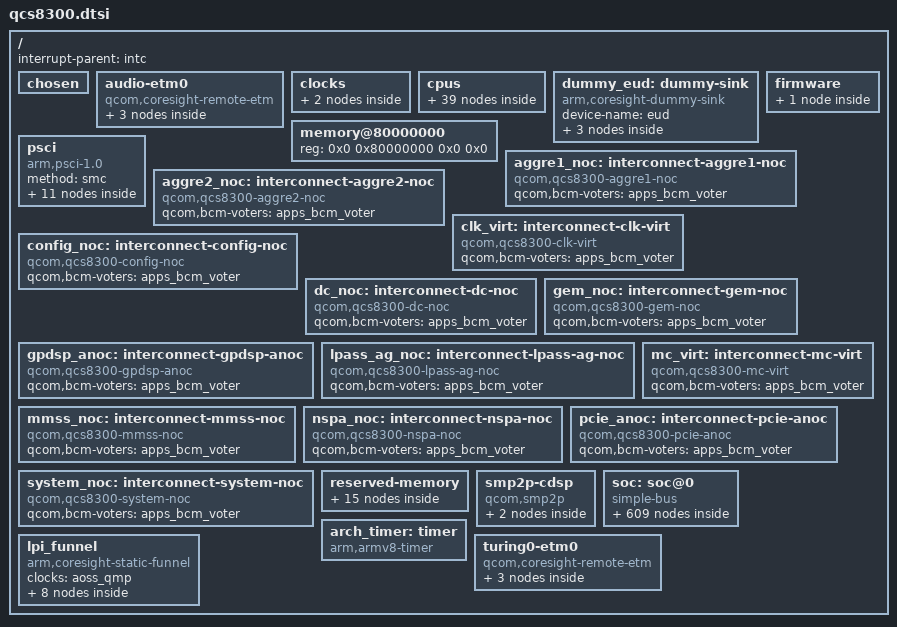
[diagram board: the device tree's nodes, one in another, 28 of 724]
// SPDX-License-Identifier: BSD-3-Clause
/*
 * Copyright (c) 2024 Qualcomm Innovation Center, Inc. All rights reserved.
 */

#include <dt-bindings/clock/qcom,qcs8300-gcc.h>
#include <dt-bindings/clock/qcom,rpmh.h>
#include <dt-bindings/clock/qcom,sa8775p-camcc.h>
#include <dt-bindings/clock/qcom,sa8775p-dispcc.h>
#include <dt-bindings/clock/qcom,sa8775p-gpucc.h>
#include <dt-bindings/clock/qcom,sa8775p-videocc.h>
#include <dt-bindings/interconnect/qcom,icc.h>
#include <dt-bindings/interconnect/qcom,qcs8300-rpmh.h>
#include <dt-bindings/interrupt-controller/arm-gic.h>
#include <dt-bindings/mailbox/qcom-ipcc.h>
#include <dt-bindings/power/qcom,rpmhpd.h>
#include <dt-bindings/power/qcom-rpmpd.h>
#include <dt-bindings/soc/qcom,rpmh-rsc.h>

/ {
	interrupt-parent = <&intc>;

	#address-cells = <2>;
	#size-cells = <2>;

	chosen { };

	audio-etm0 {
		compatible = "qcom,coresight-remote-etm";
		device-name = "audio_etm0";

		qcom,inst-id = <5>;
		atid = <40>;

		out-ports {
			port {
				audio_out: endpoint {
					remote-endpoint =
					<&lpi_funnel_in0>;
				};
			};
		};
	};

	clocks {
		xo_board: xo-board {
			compatible = "fixed-clock";
			#clock-cells = <0>;
			clock-frequency = <38400000>;
		};

		sleep_clk: sleep-clk {
			compatible = "fixed-clock";
			#clock-cells = <0>;
			clock-frequency = <32000>;
		};
	};

	cpus {
		#address-cells = <2>;
		#size-cells = <0>;

		CPU0: cpu@0 {
			device_type = "cpu";
			compatible = "arm,cortex-a78c";
			reg = <0x0 0x0>;
			enable-method = "psci";
			next-level-cache = <&L2_0>;
			power-domains = <&CPU_PD0>;
			power-domain-names = "psci";
			qcom,freq-domain = <&cpufreq_hw 0>;

			L2_0: l2-cache {
				compatible = "cache";
				cache-level = <2>;
				cache-unified;
				next-level-cache = <&L3_0>;

				L3_0: l3-cache {
					compatible = "cache";
					cache-level = <3>;
					cache-unified;
				};
			};
		};

		CPU1: cpu@100 {
			device_type = "cpu";
			compatible = "arm,cortex-a78c";
			reg = <0x0 0x100>;
			enable-method = "psci";
			next-level-cache = <&L2_1>;
			power-domains = <&CPU_PD1>;
			power-domain-names = "psci";
			qcom,freq-domain = <&cpufreq_hw 0>;

			L2_1: l2-cache {
				compatible = "cache";
				cache-level = <2>;
				cache-unified;
				next-level-cache = <&L3_0>;
			};
		};

		CPU2: cpu@200 {
			device_type = "cpu";
			compatible = "arm,cortex-a78c";
			reg = <0x0 0x200>;
			enable-method = "psci";
			next-level-cache = <&L2_2>;
			power-domains = <&CPU_PD2>;
			power-domain-names = "psci";
			qcom,freq-domain = <&cpufreq_hw 1>;

			L2_2: l2-cache {
				compatible = "cache";
				cache-level = <2>;
				cache-unified;
				next-level-cache = <&L3_0>;
			};
		};

		CPU3: cpu@300 {
			device_type = "cpu";
			compatible = "arm,cortex-a78c";
			reg = <0x0 0x300>;
			enable-method = "psci";
			next-level-cache = <&L2_3>;
			power-domains = <&CPU_PD3>;
			power-domain-names = "psci";
			qcom,freq-domain = <&cpufreq_hw 1>;

			L2_3: l2-cache {
				compatible = "cache";
				cache-level = <2>;
				cache-unified;
				next-level-cache = <&L3_0>;
			};
		};

		CPU4: cpu@10000 {
			device_type = "cpu";
			compatible = "arm,cortex-a55";
			reg = <0x0 0x10000>;
			enable-method = "psci";
			next-level-cache = <&L2_4>;
			power-domains = <&CPU_PD4>;
			power-domain-names = "psci";
			qcom,freq-domain = <&cpufreq_hw 2>;

			L2_4: l2-cache {
				compatible = "cache";
				cache-level = <2>;
				cache-unified;
				next-level-cache = <&L3_1>;

				L3_1: l3-cache {
					compatible = "cache";
					cache-level = <3>;
					cache-unified;
				};
			};
		};

		CPU5: cpu@10100 {
			device_type = "cpu";
			compatible = "arm,cortex-a55";
			reg = <0x0 0x10100>;
			enable-method = "psci";
			next-level-cache = <&L2_5>;
			power-domains = <&CPU_PD5>;
			power-domain-names = "psci";
			qcom,freq-domain = <&cpufreq_hw 2>;

			L2_5: l2-cache {
				compatible = "cache";
				cache-level = <2>;
				cache-unified;
				next-level-cache = <&L3_1>;
			};
		};

		CPU6: cpu@10200 {
			device_type = "cpu";
			compatible = "arm,cortex-a55";
			reg = <0x0 0x10200>;
			enable-method = "psci";
			next-level-cache = <&L2_6>;
			power-domains = <&CPU_PD6>;
			power-domain-names = "psci";
			qcom,freq-domain = <&cpufreq_hw 2>;

			L2_6: l2-cache {
				compatible = "cache";
				cache-level = <2>;
				cache-unified;
				next-level-cache = <&L3_1>;
			};
		};

		CPU7: cpu@10300 {
			device_type = "cpu";
			compatible = "arm,cortex-a55";
			reg = <0x0 0x10300>;
			enable-method = "psci";
			next-level-cache = <&L2_7>;
			power-domains = <&CPU_PD7>;
			power-domain-names = "psci";
			qcom,freq-domain = <&cpufreq_hw 2>;

			L2_7: l2-cache {
				compatible = "cache";
				cache-level = <2>;
				cache-unified;
				next-level-cache = <&L3_1>;
			};
		};

		cpu-map {
			cluster0 {
				core0 {
					cpu = <&CPU0>;
				};

				core1 {
					cpu = <&CPU1>;
				};
			};

			cluster1 {
				core0 {
					cpu = <&CPU2>;
				};

				core1 {
					cpu = <&CPU3>;
				};
			};

			cluster2 {
				core0 {
					cpu = <&CPU4>;
				};

				core1 {
					cpu = <&CPU5>;
				};

				core2 {
					cpu = <&CPU6>;
				};

				core3 {
					cpu = <&CPU7>;
				};
			};
		};

		idle-states {
			entry-method = "psci";

			LITTLE_CPU_SLEEP_0: cpu-sleep-0-0 {
				compatible = "arm,idle-state";
				idle-state-name = "silver-power-collapse";
				arm,psci-suspend-param = <0x40000003>;
				entry-latency-us = <449>;
				exit-latency-us = <801>;
				min-residency-us = <1574>;
				local-timer-stop;
			};

			LITTLE_CPU_SLEEP_1: cpu-sleep-0-1 {
				compatible = "arm,idle-state";
				idle-state-name = "silver-rail-power-collapse";
				arm,psci-suspend-param = <0x40000004>;
				entry-latency-us = <602>;
				exit-latency-us = <961>;
				min-residency-us = <4288>;
				local-timer-stop;
			};

			BIG_CPU_SLEEP_0: cpu-sleep-1-0 {
				compatible = "arm,idle-state";
				idle-state-name = "gold-power-collapse";
				arm,psci-suspend-param = <0x40000003>;
				entry-latency-us = <549>;
				exit-latency-us = <901>;
				min-residency-us = <1774>;
				local-timer-stop;
			};

			BIG_CPU_SLEEP_1: cpu-sleep-1-1 {
				compatible = "arm,idle-state";
				idle-state-name = "gold-rail-power-collapse";
				arm,psci-suspend-param = <0x40000004>;
				entry-latency-us = <702>;
				exit-latency-us = <1061>;
				min-residency-us = <4488>;
				local-timer-stop;
			};
		};

		domain-idle-states {
			SILVER_CLUSTER_SLEEP: cluster-sleep-0 {
				compatible = "domain-idle-state";
				arm,psci-suspend-param = <0x41000044>;
				entry-latency-us = <2552>;
				exit-latency-us = <2848>;
				min-residency-us = <5908>;
			};

			GOLD_CLUSTER_SLEEP: cluster-sleep-1 {
				compatible = "domain-idle-state";
				arm,psci-suspend-param = <0x41000044>;
				entry-latency-us = <2752>;
				exit-latency-us = <3048>;
				min-residency-us = <6118>;
			};

			SYSTEM_SLEEP: domain-sleep {
				compatible = "domain-idle-state";
				arm,psci-suspend-param = <0x42000144>;
				entry-latency-us = <3263>;
				exit-latency-us = <6562>;
				min-residency-us = <9987>;
			};
		};
	};

	dummy_eud: dummy-sink {
		compatible = "arm,coresight-dummy-sink";
		device-name = "eud";

		in-ports {
			port {
				eud_in: endpoint {
					remote-endpoint =
					<&swao_rep_out1>;
				};
			};
		};
	};

	firmware {
		scm: scm {
			compatible = "qcom,scm-qcs8300", "qcom,scm";
			qcom,dload-mode = <&tcsr 0x13000>;
		};
	};

	memory@80000000 {
		device_type = "memory";
		/* We expect the bootloader to fill in the size */
		reg = <0x0 0x80000000 0x0 0x0>;
	};

	psci {
		compatible = "arm,psci-1.0";
		method = "smc";

		CPU_PD0: power-domain-cpu0 {
			#power-domain-cells = <0>;
			power-domains = <&CLUSTER_PD0>;
			domain-idle-states = <&BIG_CPU_SLEEP_0 &BIG_CPU_SLEEP_1>;
		};

		CPU_PD1: power-domain-cpu1 {
			#power-domain-cells = <0>;
			power-domains = <&CLUSTER_PD0>;
			domain-idle-states = <&BIG_CPU_SLEEP_0 &BIG_CPU_SLEEP_1>;
		};

		CPU_PD2: power-domain-cpu2 {
			#power-domain-cells = <0>;
			power-domains = <&CLUSTER_PD0>;
			domain-idle-states = <&BIG_CPU_SLEEP_0 &BIG_CPU_SLEEP_1>;
		};

		CPU_PD3: power-domain-cpu3 {
			#power-domain-cells = <0>;
			power-domains = <&CLUSTER_PD0>;
			domain-idle-states = <&BIG_CPU_SLEEP_0 &BIG_CPU_SLEEP_1>;
		};

		CPU_PD4: power-domain-cpu4 {
			#power-domain-cells = <0>;
			power-domains = <&CLUSTER_PD1>;
			domain-idle-states = <&LITTLE_CPU_SLEEP_0 &LITTLE_CPU_SLEEP_1>;
		};

		CPU_PD5: power-domain-cpu5 {
			#power-domain-cells = <0>;
			power-domains = <&CLUSTER_PD1>;
			domain-idle-states = <&LITTLE_CPU_SLEEP_0 &LITTLE_CPU_SLEEP_1>;
		};

		CPU_PD6: power-domain-cpu6 {
			#power-domain-cells = <0>;
			power-domains = <&CLUSTER_PD1>;
			domain-idle-states = <&LITTLE_CPU_SLEEP_0 &LITTLE_CPU_SLEEP_1>;
		};

		CPU_PD7: power-domain-cpu7 {
			#power-domain-cells = <0>;
			power-domains = <&CLUSTER_PD1>;
			domain-idle-states = <&LITTLE_CPU_SLEEP_0 &LITTLE_CPU_SLEEP_1>;
		};

		CLUSTER_PD0: power-domain-cluster0 {
			#power-domain-cells = <0>;
			power-domains = <&SYSTEM_PD>;
			domain-idle-states = <&GOLD_CLUSTER_SLEEP>;
		};

		CLUSTER_PD1: power-domain-cluster1 {
			#power-domain-cells = <0>;
			power-domains = <&SYSTEM_PD>;
			domain-idle-states = <&SILVER_CLUSTER_SLEEP>;
		};

		SYSTEM_PD: power-domain-system {
			#power-domain-cells = <0>;
			domain-idle-states = <&SYSTEM_SLEEP>;
		};
	};

	aggre1_noc: interconnect-aggre1-noc {
		compatible = "qcom,qcs8300-aggre1-noc";
		#interconnect-cells = <2>;
		qcom,bcm-voters = <&apps_bcm_voter>;
	};

	aggre2_noc: interconnect-aggre2-noc {
		compatible = "qcom,qcs8300-aggre2-noc";
		#interconnect-cells = <2>;
		qcom,bcm-voters = <&apps_bcm_voter>;
	};

	clk_virt: interconnect-clk-virt {
		compatible = "qcom,qcs8300-clk-virt";
		#interconnect-cells = <2>;
		qcom,bcm-voters = <&apps_bcm_voter>;
	};

	config_noc: interconnect-config-noc {
		compatible = "qcom,qcs8300-config-noc";
		#interconnect-cells = <2>;
		qcom,bcm-voters = <&apps_bcm_voter>;
	};

	dc_noc: interconnect-dc-noc {
		compatible = "qcom,qcs8300-dc-noc";
		#interconnect-cells = <2>;
		qcom,bcm-voters = <&apps_bcm_voter>;
	};

	gem_noc: interconnect-gem-noc {
		compatible = "qcom,qcs8300-gem-noc";
		#interconnect-cells = <2>;
		qcom,bcm-voters = <&apps_bcm_voter>;
	};

	gpdsp_anoc: interconnect-gpdsp-anoc {
		compatible = "qcom,qcs8300-gpdsp-anoc";
		#interconnect-cells = <2>;
		qcom,bcm-voters = <&apps_bcm_voter>;
	};

	lpass_ag_noc: interconnect-lpass-ag-noc {
		compatible = "qcom,qcs8300-lpass-ag-noc";
		#interconnect-cells = <2>;
		qcom,bcm-voters = <&apps_bcm_voter>;
	};

	mc_virt: interconnect-mc-virt {
		compatible = "qcom,qcs8300-mc-virt";
		#interconnect-cells = <2>;
		qcom,bcm-voters = <&apps_bcm_voter>;
	};

	mmss_noc: interconnect-mmss-noc {
		compatible = "qcom,qcs8300-mmss-noc";
		#interconnect-cells = <2>;
		qcom,bcm-voters = <&apps_bcm_voter>;
	};

	nspa_noc: interconnect-nspa-noc {
		compatible = "qcom,qcs8300-nspa-noc";
		#interconnect-cells = <2>;
		qcom,bcm-voters = <&apps_bcm_voter>;
	};

	pcie_anoc: interconnect-pcie-anoc {
		compatible = "qcom,qcs8300-pcie-anoc";
		#interconnect-cells = <2>;
		qcom,bcm-voters = <&apps_bcm_voter>;
	};

	system_noc: interconnect-system-noc {
		compatible = "qcom,qcs8300-system-noc";
		#interconnect-cells = <2>;
		qcom,bcm-voters = <&apps_bcm_voter>;
	};

	reserved-memory {
		#address-cells = <2>;
		#size-cells = <2>;
		ranges;

		aop_image_mem: aop-image-region@90800000 {
			reg = <0x0 0x90800000 0x0 0x60000>;
			no-map;
		};

		aop_cmd_db_mem: aop-cmd-db-region@90860000 {
			compatible = "qcom,cmd-db";
			reg = <0x0 0x90860000 0x0 0x20000>;
			no-map;
		};

		smem_mem: smem@90900000 {
			compatible = "qcom,smem";
			reg = <0x0 0x90900000 0x0 0x200000>;
			no-map;
			hwlocks = <&tcsr_mutex 3>;
		};

		lpass_machine_learning_mem: lpass-machine-learning-region@93b00000 {
			reg = <0x0 0x93b00000 0x0 0xf00000>;
			no-map;
		};

		adsp_rpc_remote_heap_mem: adsp-rpc-remote-heap-region@94a00000 {
			reg = <0x0 0x94a00000 0x0 0x800000>;
			no-map;
		};

		camera_mem: camera-region@95200000 {
			reg = <0x0 0x95200000 0x0 0x500000>;
			no-map;
		};

		adsp_mem: adsp-region@95c00000 {
			no-map;
			reg = <0x0 0x95c00000 0x0 0x1e00000>;
		};

		q6_adsp_dtb_mem: q6-adsp-dtb-region@97a00000 {
			reg = <0x0 0x97a00000 0x0 0x80000>;
			no-map;
		};

		q6_gpdsp_dtb_mem: q6-gpdsp-dtb-region@97a80000 {
			reg = <0x0 0x97a80000 0x0 0x80000>;
			no-map;
		};

		gpdsp_mem: gpdsp-region@97b00000 {
			reg = <0x0 0x97b00000 0x0 0x1e00000>;
			no-map;
		};

		q6_cdsp_dtb_mem: q6-cdsp-dtb-region@99900000 {
			reg = <0x0 0x99900000 0x0 0x80000>;
			no-map;
		};

		cdsp_mem: cdsp-region@99980000 {
			reg = <0x0 0x99980000 0x0 0x1e00000>;
			no-map;
		};

		gpu_microcode_mem: gpu-microcode-region@9b780000 {
			reg = <0x0 0x9b780000 0x0 0x2000>;
			no-map;
		};

		cvp_mem: cvp-region@9b782000 {
			reg = <0x0 0x9b782000 0x0 0x700000>;
			no-map;
		};

		video_mem: video-region@9be82000 {
			reg = <0x0 0x9be82000 0x0 0x700000>;
			no-map;
		};
	};

	smp2p-cdsp {
		compatible = "qcom,smp2p";
		qcom,smem = <94>, <432>;
		interrupts-extended = <&ipcc IPCC_CLIENT_CDSP
					     IPCC_MPROC_SIGNAL_SMP2P
					     IRQ_TYPE_EDGE_RISING>;
		mboxes = <&ipcc IPCC_CLIENT_CDSP
				IPCC_MPROC_SIGNAL_SMP2P>;

		qcom,local-pid = <0>;
		qcom,remote-pid = <5>;

		smp2p_cdsp_out: master-kernel {
			qcom,entry-name = "master-kernel";
			#qcom,smem-state-cells = <1>;
		};

		smp2p_cdsp_in: slave-kernel {
			qcom,entry-name = "slave-kernel";
			interrupt-controller;
			#interrupt-cells = <2>;
		};
	};

	soc: soc@0 {
		compatible = "simple-bus";
		ranges = <0 0 0 0 0x10 0>;
		#address-cells = <2>;
		#size-cells = <2>;

		ethernet0: ethernet@23040000 {
			compatible = "qcom,qcs8300-ethqos";
			reg = <0x0 0x23040000 0x0 0x10000>,
			      <0x0 0x23056000 0x0 0x100>;
			reg-names = "stmmaceth", "rgmii";

			interrupts = <GIC_SPI 946 IRQ_TYPE_LEVEL_HIGH>,
				     <GIC_SPI 783 IRQ_TYPE_LEVEL_HIGH>;
			interrupt-names = "macirq", "sfty";

			clocks = <&gcc GCC_EMAC0_AXI_CLK>,
				 <&gcc GCC_EMAC0_SLV_AHB_CLK>,
				 <&gcc GCC_EMAC0_PTP_CLK>,
				 <&gcc GCC_EMAC0_PHY_AUX_CLK>;
			clock-names = "stmmaceth",
				      "pclk",
				      "ptp_ref",
				      "phyaux";
			power-domains = <&gcc GCC_EMAC0_GDSC>;

			phys = <&serdes0>;
			phy-names = "serdes";

			iommus = <&apps_smmu 0x120 0xf>;
			dma-coherent;

			snps,tso;
			snps,pbl = <32>;
			rx-fifo-depth = <16384>;
			tx-fifo-depth = <20480>;

			status = "disabled";
		};

		gcc: clock-controller@100000 {
			compatible = "qcom,qcs8300-gcc";
			reg = <0x0 0x00100000 0x0 0xc7018>;
			#clock-cells = <1>;
			#reset-cells = <1>;
			#power-domain-cells = <1>;
			clocks = <&rpmhcc RPMH_CXO_CLK>,
				 <&sleep_clk>,
				 <0>,
				 <0>,
				 <0>,
				 <0>,
				 <0>,
				 <0>,
				 <0>,
				 <0>;
		};

		ipcc: mailbox@408000 {
			compatible = "qcom,qcs8300-ipcc", "qcom,ipcc";
			reg = <0x0 0x408000 0x0 0x1000>;
			interrupts = <GIC_SPI 229 IRQ_TYPE_LEVEL_HIGH>;
			interrupt-controller;
			#interrupt-cells = <3>;
			#mbox-cells = <2>;
		};

		qfprom: efuse@784000 {
			compatible = "qcom,qcs8300-qfprom", "qcom,qfprom";
			reg = <0x0 0x00784000 0x0 0x11d0>;
			#address-cells = <1>;
			#size-cells = <1>;
		};

		qupv3_id_0: geniqup@9c0000 {
			compatible = "qcom,geni-se-qup";
			reg = <0x0 0x9c0000 0x0 0x2000>;
			ranges;
			clocks = <&gcc GCC_QUPV3_WRAP_0_M_AHB_CLK>,
				 <&gcc GCC_QUPV3_WRAP_0_S_AHB_CLK>;
			clock-names = "m-ahb", "s-ahb";
			#address-cells = <2>;
			#size-cells = <2>;
			status = "disabled";

			uart7: serial@99c000 {
				compatible = "qcom,geni-debug-uart";
				reg = <0x0 0x0099c000 0x0 0x4000>;
				clocks = <&gcc GCC_QUPV3_WRAP0_S7_CLK>;
				clock-names = "se";
				pinctrl-names = "default";
				pinctrl-0 = <&qup_uart7_default>;
				interrupts = <GIC_SPI 126 IRQ_TYPE_LEVEL_HIGH>;
				interconnect-names = "qup-core", "qup-config";
				interconnects = <&clk_virt MASTER_QUP_CORE_0 0
						 &clk_virt SLAVE_QUP_CORE_0 0>,
						<&gem_noc MASTER_APPSS_PROC 0
						 &config_noc SLAVE_QUP_0 0>;
				status = "disabled";
			};
		};

		ufs_mem_hc: ufs@1d84000 {
			compatible = "qcom,qcs8300-ufshc", "qcom,ufshc", "jedec,ufs-2.0";
			reg = <0x0 0x01d84000 0x0 0x3000>;
			interrupts = <GIC_SPI 265 IRQ_TYPE_LEVEL_HIGH>;
			phys = <&ufs_mem_phy>;
			phy-names = "ufsphy";
			lanes-per-direction = <2>;
			#reset-cells = <1>;
			reset-gpios = <&tlmm 133 1>;
			resets = <&gcc GCC_UFS_PHY_BCR>;
			reset-names = "rst";

			power-domains = <&gcc GCC_UFS_PHY_GDSC>;
			required-opps = <&rpmhpd_opp_nom>;

			iommus = <&apps_smmu 0x100 0x0>;
			dma-coherent;

			interconnects = <&aggre1_noc MASTER_UFS_MEM 0
					&mc_virt SLAVE_EBI1 0>,
					<&gem_noc MASTER_APPSS_PROC 0
					&config_noc SLAVE_UFS_MEM_CFG 0>;
			interconnect-names = "ufs-ddr", "cpu-ufs";

			clocks = <&gcc GCC_UFS_PHY_AXI_CLK>,
				 <&gcc GCC_AGGRE_UFS_PHY_AXI_CLK>,
				 <&gcc GCC_UFS_PHY_AHB_CLK>,
				 <&gcc GCC_UFS_PHY_UNIPRO_CORE_CLK>,
				 <&rpmhcc RPMH_CXO_CLK>,
				 <&gcc GCC_UFS_PHY_TX_SYMBOL_0_CLK>,
				 <&gcc GCC_UFS_PHY_RX_SYMBOL_0_CLK>,
				 <&gcc GCC_UFS_PHY_RX_SYMBOL_1_CLK>;
			clock-names = "core_clk",
				      "bus_aggr_clk",
				      "iface_clk",
				      "core_clk_unipro",
				      "ref_clk",
				      "tx_lane0_sync_clk",
				      "rx_lane0_sync_clk",
				      "rx_lane1_sync_clk";
			freq-table-hz = <75000000 300000000>,
					<0 0>,
					<0 0>,
					<75000000 300000000>,
					<0 0>,
					<0 0>,
					<0 0>,
					<0 0>;
			status = "disabled";
		};

		ufs_mem_phy: phy@1d87000 {
			compatible = "qcom,qcs8300-qmp-ufs-phy";
			reg = <0x0 0x01d87000 0x0 0xe10>;
			/*
			 * Yes, GCC_EDP_REF_CLKREF_EN is correct in qref. It
			 * enables the CXO clock to eDP *and* UFS PHY.
			 */
			clocks = <&rpmhcc RPMH_CXO_CLK>,
				 <&gcc GCC_UFS_PHY_PHY_AUX_CLK>,
				 <&gcc GCC_EDP_REF_CLKREF_EN>;
			clock-names = "ref", "ref_aux", "qref";
			power-domains = <&gcc GCC_UFS_PHY_GDSC>;

			resets = <&ufs_mem_hc 0>;
			reset-names = "ufsphy";

			#phy-cells = <0>;
			status = "disabled";
		};

		serdes0: phy@8909000 {
			compatible = "qcom,qcs8300-dwmac-sgmii-phy";
			reg = <0x0 0x8909000 0x0 0xe10>;
			clocks = <&gcc GCC_SGMI_CLKREF_EN>;
			clock-names = "sgmi_ref";
			#phy-cells = <0>;
			status = "disabled";
		};

		tcsr_mutex: hwlock@1f40000 {
			compatible = "qcom,tcsr-mutex";
			reg = <0x0 0x01f40000 0x0 0x20000>;
			#hwlock-cells = <1>;
		};

		gpucc: clock-controller@3d90000 {
			compatible = "qcom,qcs8300-gpucc";
			reg = <0x0 0x03d90000 0x0 0xa000>;
			clocks = <&rpmhcc RPMH_CXO_CLK>,
				 <&gcc GCC_GPU_GPLL0_CLK_SRC>,
				 <&gcc GCC_GPU_GPLL0_DIV_CLK_SRC>;
			clock-names = "bi_tcxo",
				      "gcc_gpu_gpll0_clk_src",
				      "gcc_gpu_gpll0_div_clk_src";
			#clock-cells = <1>;
			#reset-cells = <1>;
			#power-domain-cells = <1>;
		};

		adreno_smmu: iommu@3da0000 {
			compatible = "qcom,qcs8300-smmu-500", "qcom,adreno-smmu",
				     "qcom,smmu-500", "arm,mmu-500";
			reg = <0x0 0x3da0000 0x0 0x20000>;
			#iommu-cells = <2>;
			#global-interrupts = <2>;
			dma-coherent;

			power-domains = <&gpucc GPU_CC_CX_GDSC>;
			clocks = <&gcc GCC_GPU_MEMNOC_GFX_CLK>,
				 <&gcc GCC_GPU_SNOC_DVM_GFX_CLK>,
				 <&gpucc GPU_CC_AHB_CLK>,
				 <&gpucc GPU_CC_HLOS1_VOTE_GPU_SMMU_CLK>,
				 <&gpucc GPU_CC_CX_GMU_CLK>,
				 <&gpucc GPU_CC_HUB_CX_INT_CLK>,
				 <&gpucc GPU_CC_HUB_AON_CLK>;
			clock-names = "gcc_gpu_memnoc_gfx_clk",
				      "gcc_gpu_snoc_dvm_gfx_clk",
				      "gpu_cc_ahb_clk",
				      "gpu_cc_hlos1_vote_gpu_smmu_clk",
				      "gpu_cc_cx_gmu_clk",
				      "gpu_cc_hub_cx_int_clk",
				      "gpu_cc_hub_aon_clk";
			interrupts = <GIC_SPI 672 IRQ_TYPE_LEVEL_HIGH>,
				     <GIC_SPI 673 IRQ_TYPE_LEVEL_HIGH>,
				     <GIC_SPI 678 IRQ_TYPE_LEVEL_HIGH>,
				     <GIC_SPI 679 IRQ_TYPE_LEVEL_HIGH>,
				     <GIC_SPI 680 IRQ_TYPE_LEVEL_HIGH>,
				     <GIC_SPI 681 IRQ_TYPE_LEVEL_HIGH>,
				     <GIC_SPI 682 IRQ_TYPE_LEVEL_HIGH>,
				     <GIC_SPI 683 IRQ_TYPE_LEVEL_HIGH>,
				     <GIC_SPI 684 IRQ_TYPE_LEVEL_HIGH>,
				     <GIC_SPI 685 IRQ_TYPE_LEVEL_HIGH>,
				     <GIC_SPI 686 IRQ_TYPE_LEVEL_HIGH>,
				     <GIC_SPI 687 IRQ_TYPE_LEVEL_HIGH>;
		};

		llcc: system-cache-controller@9200000 {
			compatible = "qcom,qcs8300-llcc";
			reg = <0x0 0x09200000 0x0 0x80000>,
			      <0x0 0x09300000 0x0 0x80000>,
			      <0x0 0x09400000 0x0 0x80000>,
			      <0x0 0x09500000 0x0 0x80000>,
			      <0x0 0x09a00000 0x0 0x80000>;
			reg-names = "llcc0_base",
				    "llcc1_base",
				    "llcc2_base",
				    "llcc3_base",
				    "llcc_broadcast_base";
			interrupts = <GIC_SPI 582 IRQ_TYPE_LEVEL_HIGH>;
			num-banks = <4>;
		};

		videocc: clock-controller@abf0000 {
			compatible = "qcom,sa8775p-videocc";
			reg = <0x0 0x0abf0000 0x0 0x10000>;
			clocks = <&gcc GCC_VIDEO_AHB_CLK>,
				 <&rpmhcc RPMH_CXO_CLK>,
				 <&rpmhcc RPMH_CXO_CLK_A>,
				 <&sleep_clk>;
			power-domains = <&rpmhpd QCS8300_MMCX>;
			required-opps = <&rpmhpd_opp_low_svs>;
			#clock-cells = <1>;
			#reset-cells = <1>;
			#power-domain-cells = <1>;
		};

		camcc: clock-controller@ade0000 {
			compatible = "qcom,qcs8300-camcc";
			reg = <0x0 0x0ade0000 0x0 0x20000>;
			clocks = <&gcc GCC_CAMERA_AHB_CLK>,
				 <&rpmhcc RPMH_CXO_CLK>,
				 <&rpmhcc RPMH_CXO_CLK_A>,
				 <&sleep_clk>;
			power-domains = <&rpmhpd QCS8300_MMCX>;
			required-opps = <&rpmhpd_opp_low_svs>;
			#clock-cells = <1>;
			#reset-cells = <1>;
			#power-domain-cells = <1>;
		};

		dispcc0: clock-controller@af00000 {
			compatible = "qcom,sa8775p-dispcc0";
			reg = <0x0 0x0af00000 0x0 0x20000>;
			clocks = <&gcc GCC_DISP_AHB_CLK>,
				 <&rpmhcc RPMH_CXO_CLK>,
				 <&rpmhcc RPMH_CXO_CLK_A>,
				 <&sleep_clk>,
				 <0>, <0>, <0>, <0>,
				 <0>, <0>, <0>, <0>;
			power-domains = <&rpmhpd QCS8300_MMCX>;
			required-opps = <&rpmhpd_opp_low_svs>;
			#clock-cells = <1>;
			#reset-cells = <1>;
			#power-domain-cells = <1>;
		};

		pdc: interrupt-controller@b220000 {
			compatible = "qcom,qcs8300-pdc", "qcom,pdc";
			reg = <0x0 0xb220000 0x0 0x30000>,
			      <0x0 0x17c000f0 0x0 0x64>;
			qcom,pdc-ranges = <0 480 40>,
					  <40 140 14>,
					  <54 263 1>,
					  <55 306 4>,
					  <59 312 3>,
					  <62 374 2>,
					  <64 434 2>,
					  <66 438 2>,
					  <70 520 1>,
					  <73 523 1>,
					  <118 568 6>,
					  <124 609 3>,
					  <159 638 1>,
					  <160 720 3>,
					  <169 728 30>,
					  <199 416 2>,
					  <201 449 1>,
					  <202 89 1>,
					  <203 451 1>,
					  <204 462 1>,
					  <205 264 1>,
					  <206 579 1>,
					  <207 653 1>,
					  <208 656 1>,
					  <209 659 1>,
					  <210 122 1>,
					  <211 699 1>,
					  <212 705 1>,
					  <213 450 1>,
					  <214 643 2>,
					  <216 646 5>,
					  <221 390 5>,
					  <226 700 2>,
					  <228 440 1>,
					  <229 663 1>,
					  <230 524 2>,
					  <232 612 3>,
					  <235 723 5>;
			interrupt-parent = <&intc>;
			#interrupt-cells = <2>;
			interrupt-controller;
		};

		aoss_qmp: power-management@c300000 {
			compatible = "qcom,qcs8300-aoss-qmp", "qcom,aoss-qmp";
			reg = <0x0 0x0c300000 0x0 0x400>;
			interrupts-extended = <&ipcc IPCC_CLIENT_AOP
					       IPCC_MPROC_SIGNAL_GLINK_QMP
					       IRQ_TYPE_EDGE_RISING>;
			mboxes = <&ipcc IPCC_CLIENT_AOP IPCC_MPROC_SIGNAL_GLINK_QMP>;
			#clock-cells = <0>;
		};

		intc: interrupt-controller@17a00000 {
			compatible = "arm,gic-v3";
			reg = <0x0 0x17a00000 0x0 0x10000>,     /* GICD */
			      <0x0 0x17a60000 0x0 0x100000>;    /* GICR * 8 */
			interrupts = <GIC_PPI 9 IRQ_TYPE_LEVEL_HIGH>;
			#interrupt-cells = <3>;
			interrupt-controller;
			#redistributor-regions = <1>;
			redistributor-stride = <0x0 0x20000>;
		};

		sram: sram@146d8000 {
			compatible = "qcom,qcs8300-imem", "syscon", "simple-mfd";
			reg = <0x0 0x146d8000 0x0 0x1000>;

			#address-cells = <1>;
			#size-cells = <1>;

			ranges = <0x0 0x0 0x146d8000 0x1000>;

			pil-reloc@94c {
				compatible = "qcom,pil-reloc-info";
				reg = <0x94c 0xc8>;
			};
		};

		apps_smmu: iommu@15000000 {
			compatible = "qcom,qcs8300-smmu-500", "qcom,smmu-500", "arm,mmu-500";

			reg = <0x0 0x15000000 0x0 0x100000>;
			#iommu-cells = <2>;
			#global-interrupts = <2>;
			dma-coherent;

			interrupts = <GIC_SPI 119 IRQ_TYPE_LEVEL_HIGH>,
				     <GIC_SPI 120 IRQ_TYPE_LEVEL_HIGH>,
				     <GIC_SPI  98 IRQ_TYPE_LEVEL_HIGH>,
				     <GIC_SPI  99 IRQ_TYPE_LEVEL_HIGH>,
				     <GIC_SPI 100 IRQ_TYPE_LEVEL_HIGH>,
				     <GIC_SPI 101 IRQ_TYPE_LEVEL_HIGH>,
				     <GIC_SPI 102 IRQ_TYPE_LEVEL_HIGH>,
				     <GIC_SPI 103 IRQ_TYPE_LEVEL_HIGH>,
				     <GIC_SPI 104 IRQ_TYPE_LEVEL_HIGH>,
				     <GIC_SPI 105 IRQ_TYPE_LEVEL_HIGH>,
				     <GIC_SPI 106 IRQ_TYPE_LEVEL_HIGH>,
				     <GIC_SPI 107 IRQ_TYPE_LEVEL_HIGH>,
				     <GIC_SPI 108 IRQ_TYPE_LEVEL_HIGH>,
				     <GIC_SPI 109 IRQ_TYPE_LEVEL_HIGH>,
				     <GIC_SPI 110 IRQ_TYPE_LEVEL_HIGH>,
				     <GIC_SPI 111 IRQ_TYPE_LEVEL_HIGH>,
				     <GIC_SPI 112 IRQ_TYPE_LEVEL_HIGH>,
				     <GIC_SPI 113 IRQ_TYPE_LEVEL_HIGH>,
				     <GIC_SPI 114 IRQ_TYPE_LEVEL_HIGH>,
				     <GIC_SPI 115 IRQ_TYPE_LEVEL_HIGH>,
				     <GIC_SPI 116 IRQ_TYPE_LEVEL_HIGH>,
				     <GIC_SPI 117 IRQ_TYPE_LEVEL_HIGH>,
				     <GIC_SPI 118 IRQ_TYPE_LEVEL_HIGH>,
				     <GIC_SPI 181 IRQ_TYPE_LEVEL_HIGH>,
				     <GIC_SPI 182 IRQ_TYPE_LEVEL_HIGH>,
				     <GIC_SPI 183 IRQ_TYPE_LEVEL_HIGH>,
				     <GIC_SPI 184 IRQ_TYPE_LEVEL_HIGH>,
				     <GIC_SPI 185 IRQ_TYPE_LEVEL_HIGH>,
				     <GIC_SPI 186 IRQ_TYPE_LEVEL_HIGH>,
				     <GIC_SPI 187 IRQ_TYPE_LEVEL_HIGH>,
				     <GIC_SPI 188 IRQ_TYPE_LEVEL_HIGH>,
				     <GIC_SPI 189 IRQ_TYPE_LEVEL_HIGH>,
				     <GIC_SPI 190 IRQ_TYPE_LEVEL_HIGH>,
				     <GIC_SPI 191 IRQ_TYPE_LEVEL_HIGH>,
				     <GIC_SPI 192 IRQ_TYPE_LEVEL_HIGH>,
				     <GIC_SPI 315 IRQ_TYPE_LEVEL_HIGH>,
				     <GIC_SPI 316 IRQ_TYPE_LEVEL_HIGH>,
				     <GIC_SPI 317 IRQ_TYPE_LEVEL_HIGH>,
				     <GIC_SPI 318 IRQ_TYPE_LEVEL_HIGH>,
				     <GIC_SPI 319 IRQ_TYPE_LEVEL_HIGH>,
				     <GIC_SPI 320 IRQ_TYPE_LEVEL_HIGH>,
				     <GIC_SPI 321 IRQ_TYPE_LEVEL_HIGH>,
				     <GIC_SPI 322 IRQ_TYPE_LEVEL_HIGH>,
				     <GIC_SPI 323 IRQ_TYPE_LEVEL_HIGH>,
				     <GIC_SPI 324 IRQ_TYPE_LEVEL_HIGH>,
				     <GIC_SPI 325 IRQ_TYPE_LEVEL_HIGH>,
				     <GIC_SPI 326 IRQ_TYPE_LEVEL_HIGH>,
				     <GIC_SPI 327 IRQ_TYPE_LEVEL_HIGH>,
				     <GIC_SPI 328 IRQ_TYPE_LEVEL_HIGH>,
				     <GIC_SPI 329 IRQ_TYPE_LEVEL_HIGH>,
				     <GIC_SPI 330 IRQ_TYPE_LEVEL_HIGH>,
				     <GIC_SPI 331 IRQ_TYPE_LEVEL_HIGH>,
				     <GIC_SPI 332 IRQ_TYPE_LEVEL_HIGH>,
				     <GIC_SPI 333 IRQ_TYPE_LEVEL_HIGH>,
				     <GIC_SPI 334 IRQ_TYPE_LEVEL_HIGH>,
				     <GIC_SPI 335 IRQ_TYPE_LEVEL_HIGH>,
				     <GIC_SPI 336 IRQ_TYPE_LEVEL_HIGH>,
				     <GIC_SPI 337 IRQ_TYPE_LEVEL_HIGH>,
				     <GIC_SPI 338 IRQ_TYPE_LEVEL_HIGH>,
				     <GIC_SPI 339 IRQ_TYPE_LEVEL_HIGH>,
				     <GIC_SPI 340 IRQ_TYPE_LEVEL_HIGH>,
				     <GIC_SPI 341 IRQ_TYPE_LEVEL_HIGH>,
				     <GIC_SPI 342 IRQ_TYPE_LEVEL_HIGH>,
				     <GIC_SPI 343 IRQ_TYPE_LEVEL_HIGH>,
				     <GIC_SPI 344 IRQ_TYPE_LEVEL_HIGH>,
				     <GIC_SPI 345 IRQ_TYPE_LEVEL_HIGH>,
				     <GIC_SPI 395 IRQ_TYPE_LEVEL_HIGH>,
				     <GIC_SPI 396 IRQ_TYPE_LEVEL_HIGH>,
				     <GIC_SPI 397 IRQ_TYPE_LEVEL_HIGH>,
				     <GIC_SPI 398 IRQ_TYPE_LEVEL_HIGH>,
				     <GIC_SPI 399 IRQ_TYPE_LEVEL_HIGH>,
				     <GIC_SPI 400 IRQ_TYPE_LEVEL_HIGH>,
				     <GIC_SPI 401 IRQ_TYPE_LEVEL_HIGH>,
				     <GIC_SPI 402 IRQ_TYPE_LEVEL_HIGH>,
				     <GIC_SPI 403 IRQ_TYPE_LEVEL_HIGH>,
				     <GIC_SPI 404 IRQ_TYPE_LEVEL_HIGH>,
				     <GIC_SPI 405 IRQ_TYPE_LEVEL_HIGH>,
				     <GIC_SPI 406 IRQ_TYPE_LEVEL_HIGH>,
				     <GIC_SPI 407 IRQ_TYPE_LEVEL_HIGH>,
				     <GIC_SPI 408 IRQ_TYPE_LEVEL_HIGH>,
				     <GIC_SPI 409 IRQ_TYPE_LEVEL_HIGH>,
				     <GIC_SPI 418 IRQ_TYPE_LEVEL_HIGH>,
				     <GIC_SPI 419 IRQ_TYPE_LEVEL_HIGH>,
				     <GIC_SPI 412 IRQ_TYPE_LEVEL_HIGH>,
				     <GIC_SPI 421 IRQ_TYPE_LEVEL_HIGH>,
				     <GIC_SPI 706 IRQ_TYPE_LEVEL_HIGH>,
				     <GIC_SPI 423 IRQ_TYPE_LEVEL_HIGH>,
				     <GIC_SPI 424 IRQ_TYPE_LEVEL_HIGH>,
				     <GIC_SPI 425 IRQ_TYPE_LEVEL_HIGH>,
				     <GIC_SPI 689 IRQ_TYPE_LEVEL_HIGH>,
				     <GIC_SPI 690 IRQ_TYPE_LEVEL_HIGH>,
				     <GIC_SPI 691 IRQ_TYPE_LEVEL_HIGH>,
				     <GIC_SPI 692 IRQ_TYPE_LEVEL_HIGH>,
				     <GIC_SPI 693 IRQ_TYPE_LEVEL_HIGH>,
				     <GIC_SPI 694 IRQ_TYPE_LEVEL_HIGH>,
				     <GIC_SPI 695 IRQ_TYPE_LEVEL_HIGH>,
				     <GIC_SPI 696 IRQ_TYPE_LEVEL_HIGH>,
				     <GIC_SPI 410 IRQ_TYPE_LEVEL_HIGH>,
				     <GIC_SPI 411 IRQ_TYPE_LEVEL_HIGH>,
				     <GIC_SPI 420 IRQ_TYPE_LEVEL_HIGH>,
				     <GIC_SPI 413 IRQ_TYPE_LEVEL_HIGH>,
				     <GIC_SPI 422 IRQ_TYPE_LEVEL_HIGH>,
				     <GIC_SPI 707 IRQ_TYPE_LEVEL_HIGH>,
				     <GIC_SPI 708 IRQ_TYPE_LEVEL_HIGH>,
				     <GIC_SPI 709 IRQ_TYPE_LEVEL_HIGH>,
				     <GIC_SPI 710 IRQ_TYPE_LEVEL_HIGH>,
				     <GIC_SPI 711 IRQ_TYPE_LEVEL_HIGH>,
				     <GIC_SPI 414 IRQ_TYPE_LEVEL_HIGH>,
				     <GIC_SPI 712 IRQ_TYPE_LEVEL_HIGH>,
				     <GIC_SPI 713 IRQ_TYPE_LEVEL_HIGH>,
				     <GIC_SPI 714 IRQ_TYPE_LEVEL_HIGH>,
				     <GIC_SPI 715 IRQ_TYPE_LEVEL_HIGH>,
				     <GIC_SPI 912 IRQ_TYPE_LEVEL_HIGH>,
				     <GIC_SPI 911 IRQ_TYPE_LEVEL_HIGH>,
				     <GIC_SPI 910 IRQ_TYPE_LEVEL_HIGH>,
				     <GIC_SPI 909 IRQ_TYPE_LEVEL_HIGH>,
				     <GIC_SPI 908 IRQ_TYPE_LEVEL_HIGH>,
				     <GIC_SPI 907 IRQ_TYPE_LEVEL_HIGH>,
				     <GIC_SPI 906 IRQ_TYPE_LEVEL_HIGH>,
				     <GIC_SPI 905 IRQ_TYPE_LEVEL_HIGH>,
				     <GIC_SPI 904 IRQ_TYPE_LEVEL_HIGH>,
				     <GIC_SPI 903 IRQ_TYPE_LEVEL_HIGH>,
				     <GIC_SPI 902 IRQ_TYPE_LEVEL_HIGH>,
				     <GIC_SPI 901 IRQ_TYPE_LEVEL_HIGH>,
				     <GIC_SPI 900 IRQ_TYPE_LEVEL_HIGH>,
				     <GIC_SPI 899 IRQ_TYPE_LEVEL_HIGH>,
				     <GIC_SPI 898 IRQ_TYPE_LEVEL_HIGH>,
				     <GIC_SPI 897 IRQ_TYPE_LEVEL_HIGH>,
				     <GIC_SPI 896 IRQ_TYPE_LEVEL_HIGH>,
				     <GIC_SPI 895 IRQ_TYPE_LEVEL_HIGH>;
		};

		pcie_smmu: iommu@15200000 {
			compatible = "qcom,qcs8300-smmu-500", "qcom,smmu-500", "arm,mmu-500";
			reg = <0x0 0x15200000 0x0 0x80000>;
			#iommu-cells = <2>;
			#global-interrupts = <2>;
			dma-coherent;

			interrupts = <GIC_SPI 920 IRQ_TYPE_LEVEL_HIGH>,
				     <GIC_SPI 921 IRQ_TYPE_LEVEL_HIGH>,
				     <GIC_SPI 925 IRQ_TYPE_LEVEL_HIGH>,
				     <GIC_SPI 926 IRQ_TYPE_LEVEL_HIGH>,
				     <GIC_SPI 927 IRQ_TYPE_LEVEL_HIGH>,
				     <GIC_SPI 928 IRQ_TYPE_LEVEL_HIGH>,
				     <GIC_SPI 950 IRQ_TYPE_LEVEL_HIGH>,
				     <GIC_SPI 951 IRQ_TYPE_LEVEL_HIGH>,
				     <GIC_SPI 952 IRQ_TYPE_LEVEL_HIGH>,
				     <GIC_SPI 953 IRQ_TYPE_LEVEL_HIGH>,
				     <GIC_SPI 954 IRQ_TYPE_LEVEL_HIGH>,
				     <GIC_SPI 955 IRQ_TYPE_LEVEL_HIGH>,
				     <GIC_SPI 956 IRQ_TYPE_LEVEL_HIGH>,
				     <GIC_SPI 957 IRQ_TYPE_LEVEL_HIGH>,
				     <GIC_SPI 958 IRQ_TYPE_LEVEL_HIGH>,
				     <GIC_SPI 885 IRQ_TYPE_LEVEL_HIGH>,
				     <GIC_SPI 886 IRQ_TYPE_LEVEL_HIGH>,
				     <GIC_SPI 887 IRQ_TYPE_LEVEL_HIGH>,
				     <GIC_SPI 888 IRQ_TYPE_LEVEL_HIGH>,
				     <GIC_SPI 820 IRQ_TYPE_LEVEL_HIGH>,
				     <GIC_SPI 822 IRQ_TYPE_LEVEL_HIGH>,
				     <GIC_SPI 823 IRQ_TYPE_LEVEL_HIGH>,
				     <GIC_SPI 310 IRQ_TYPE_LEVEL_HIGH>,
				     <GIC_SPI 446 IRQ_TYPE_LEVEL_HIGH>,
				     <GIC_SPI 447 IRQ_TYPE_LEVEL_HIGH>,
				     <GIC_SPI 452 IRQ_TYPE_LEVEL_HIGH>,
				     <GIC_SPI 840 IRQ_TYPE_LEVEL_HIGH>,
				     <GIC_SPI 841 IRQ_TYPE_LEVEL_HIGH>,
				     <GIC_SPI 842 IRQ_TYPE_LEVEL_HIGH>,
				     <GIC_SPI 843 IRQ_TYPE_LEVEL_HIGH>,
				     <GIC_SPI 844 IRQ_TYPE_LEVEL_HIGH>,
				     <GIC_SPI 845 IRQ_TYPE_LEVEL_HIGH>,
				     <GIC_SPI 846 IRQ_TYPE_LEVEL_HIGH>,
				     <GIC_SPI 847 IRQ_TYPE_LEVEL_HIGH>,
				     <GIC_SPI 848 IRQ_TYPE_LEVEL_HIGH>,
				     <GIC_SPI 849 IRQ_TYPE_LEVEL_HIGH>,
				     <GIC_SPI 802 IRQ_TYPE_LEVEL_HIGH>,
				     <GIC_SPI 803 IRQ_TYPE_LEVEL_HIGH>,
				     <GIC_SPI 804 IRQ_TYPE_LEVEL_HIGH>,
				     <GIC_SPI 805 IRQ_TYPE_LEVEL_HIGH>,
				     <GIC_SPI 806 IRQ_TYPE_LEVEL_HIGH>,
				     <GIC_SPI 807 IRQ_TYPE_LEVEL_HIGH>,
				     <GIC_SPI 808 IRQ_TYPE_LEVEL_HIGH>,
				     <GIC_SPI 809 IRQ_TYPE_LEVEL_HIGH>,
				     <GIC_SPI 810 IRQ_TYPE_LEVEL_HIGH>,
				     <GIC_SPI 811 IRQ_TYPE_LEVEL_HIGH>,
				     <GIC_SPI 812 IRQ_TYPE_LEVEL_HIGH>,
				     <GIC_SPI 813 IRQ_TYPE_LEVEL_HIGH>,
				     <GIC_SPI 814 IRQ_TYPE_LEVEL_HIGH>,
				     <GIC_SPI 836 IRQ_TYPE_LEVEL_HIGH>,
				     <GIC_SPI 837 IRQ_TYPE_LEVEL_HIGH>,
				     <GIC_SPI 838 IRQ_TYPE_LEVEL_HIGH>,
				     <GIC_SPI 839 IRQ_TYPE_LEVEL_HIGH>,
				     <GIC_SPI 854 IRQ_TYPE_LEVEL_HIGH>,
				     <GIC_SPI 855 IRQ_TYPE_LEVEL_HIGH>,
				     <GIC_SPI 856 IRQ_TYPE_LEVEL_HIGH>,
				     <GIC_SPI 790 IRQ_TYPE_LEVEL_HIGH>,
				     <GIC_SPI 791 IRQ_TYPE_LEVEL_HIGH>,
				     <GIC_SPI 792 IRQ_TYPE_LEVEL_HIGH>,
				     <GIC_SPI 793 IRQ_TYPE_LEVEL_HIGH>,
				     <GIC_SPI 794 IRQ_TYPE_LEVEL_HIGH>,
				     <GIC_SPI 795 IRQ_TYPE_LEVEL_HIGH>,
				     <GIC_SPI 796 IRQ_TYPE_LEVEL_HIGH>,
				     <GIC_SPI 639 IRQ_TYPE_LEVEL_HIGH>,
				     <GIC_SPI 79 IRQ_TYPE_LEVEL_HIGH>,
				     <GIC_SPI 640 IRQ_TYPE_LEVEL_HIGH>;
		};

		tcsr: syscon@1fc0000 {
		       compatible = "qcom,qcs8300-tcsr", "syscon";
		       reg = <0x0 0x1fc0000 0x0 0x30000>;
		};

		memtimer: timer@17c20000 {
			compatible = "arm,armv7-timer-mem";
			reg = <0x0 0x17c20000 0x0 0x1000>;
			ranges = <0x0 0x0 0x0 0x20000000>;
			#address-cells = <1>;
			#size-cells = <1>;

			frame@17c21000 {
				reg = <0x17c21000 0x1000>,
				      <0x17c22000 0x1000>;
				frame-number = <0>;
				interrupts = <GIC_SPI 8 IRQ_TYPE_LEVEL_HIGH>,
					     <GIC_SPI 6 IRQ_TYPE_LEVEL_HIGH>;
			};

			frame@17c23000 {
				reg = <0x17c23000 0x1000>;
				frame-number = <1>;
				interrupts = <GIC_SPI 9 IRQ_TYPE_LEVEL_HIGH>;
				status = "disabled";
			};

			frame@17c25000 {
				reg = <0x17c25000 0x1000>;
				frame-number = <2>;
				interrupts = <GIC_SPI 10 IRQ_TYPE_LEVEL_HIGH>;
				status = "disabled";
			};

			frame@17c27000 {
				reg = <0x17c27000 0x1000>;
				frame-number = <3>;
				interrupts = <GIC_SPI 11 IRQ_TYPE_LEVEL_HIGH>;
				status = "disabled";
			};

			frame@17c29000 {
				reg = <0x17c29000 0x1000>;
				frame-number = <4>;
				interrupts = <GIC_SPI 12 IRQ_TYPE_LEVEL_HIGH>;
				status = "disabled";
			};

			frame@17c2b000 {
				reg = <0x17c2b000 0x1000>;
				frame-number = <5>;
				interrupts = <GIC_SPI 13 IRQ_TYPE_LEVEL_HIGH>;
				status = "disabled";
			};

			frame@17c2d000 {
				reg = <0x17c2d000 0x1000>;
				frame-number = <6>;
				interrupts = <GIC_SPI 14 IRQ_TYPE_LEVEL_HIGH>;
				status = "disabled";
			};
		};

		apps_rsc: rsc@18200000 {
			compatible = "qcom,rpmh-rsc";
			reg = <0x0 0x18200000 0x0 0x10000>,
			      <0x0 0x18210000 0x0 0x10000>,
			      <0x0 0x18220000 0x0 0x10000>;
			reg-names = "drv-0", "drv-1", "drv-2";
			interrupts = <GIC_SPI 3 IRQ_TYPE_LEVEL_HIGH>,
				     <GIC_SPI 4 IRQ_TYPE_LEVEL_HIGH>,
				     <GIC_SPI 5 IRQ_TYPE_LEVEL_HIGH>;
			qcom,tcs-offset = <0xd00>;
			qcom,drv-id = <2>;
			qcom,tcs-config = <ACTIVE_TCS 2>,
					  <SLEEP_TCS 3>,
					  <WAKE_TCS 3>,
					  <CONTROL_TCS 0>;
			label = "apps_rsc";
			power-domains = <&SYSTEM_PD>;

			apps_bcm_voter: bcm-voter {
				compatible = "qcom,bcm-voter";
			};

			rpmhcc: clock-controller {
				compatible = "qcom,sa8775p-rpmh-clk";
				#clock-cells = <1>;
				clocks = <&xo_board>;
			};

			rpmhpd: power-controller {
				compatible = "qcom,qcs8300-rpmhpd";
				#power-domain-cells = <1>;
				operating-points-v2 = <&rpmhpd_opp_table>;

				rpmhpd_opp_table: opp-table {
					compatible = "operating-points-v2";

					rpmhpd_opp_ret: opp-0 {
						opp-level = <RPMH_REGULATOR_LEVEL_RETENTION>;
					};

					rpmhpd_opp_min_svs: opp-1 {
						opp-level = <RPMH_REGULATOR_LEVEL_MIN_SVS>;
					};

					rpmhpd_opp_low_svs: opp2 {
						opp-level = <RPMH_REGULATOR_LEVEL_LOW_SVS>;
					};

					rpmhpd_opp_svs: opp3 {
						opp-level = <RPMH_REGULATOR_LEVEL_SVS>;
					};

					rpmhpd_opp_svs_l1: opp-4 {
						opp-level = <RPMH_REGULATOR_LEVEL_SVS_L1>;
					};

					rpmhpd_opp_nom: opp-5 {
						opp-level = <RPMH_REGULATOR_LEVEL_NOM>;
					};

					rpmhpd_opp_nom_l1: opp-6 {
						opp-level = <RPMH_REGULATOR_LEVEL_NOM_L1>;
					};

					rpmhpd_opp_nom_l2: opp-7 {
						opp-level = <RPMH_REGULATOR_LEVEL_NOM_L2>;
					};

					rpmhpd_opp_turbo: opp-8 {
						opp-level = <RPMH_REGULATOR_LEVEL_TURBO>;
					};

					rpmhpd_opp_turbo_l1: opp-9 {
						opp-level = <RPMH_REGULATOR_LEVEL_TURBO_L1>;
					};
				};
			};
		};

		cpufreq_hw: cpufreq@18591000 {
			compatible = "qcom,qcs8300-cpufreq-epss", "qcom,cpufreq-epss";
			reg = <0x0 0x18591000 0x0 0x1000>,
			      <0x0 0x18594000 0x0 0x1000>,
			      <0x0 0x18593000 0x0 0x1000>;
			reg-names = "freq-domain0", "freq-domain1", "freq-domain2";

			clocks = <&rpmhcc RPMH_CXO_CLK>, <&gcc GCC_GPLL0>;
			clock-names = "xo", "alternate";

			#freq-domain-cells = <1>;
		};

		remoteproc_cdsp: remoteproc@26300000 {
			compatible = "qcom,qcs8300-cdsp-pas";
			reg = <0x0 0x26300000 0x0 0x10000>;

			interrupts-extended = <&intc GIC_SPI 578 IRQ_TYPE_EDGE_RISING>,
					      <&smp2p_cdsp_in 0 IRQ_TYPE_EDGE_RISING>,
					      <&smp2p_cdsp_in 1 IRQ_TYPE_EDGE_RISING>,
					      <&smp2p_cdsp_in 2 IRQ_TYPE_EDGE_RISING>,
					      <&smp2p_cdsp_in 3 IRQ_TYPE_EDGE_RISING>;
			interrupt-names = "wdog", "fatal", "ready",
					  "handover", "stop-ack";

			clocks = <&rpmhcc RPMH_CXO_CLK>;
			clock-names = "xo";

			power-domains = <&rpmhpd RPMHPD_CX>,
					<&rpmhpd RPMHPD_MXC>,
					<&rpmhpd RPMHPD_NSP0>;

			power-domain-names = "cx", "mxc", "nsp0";

			interconnects = <&nspa_noc MASTER_CDSP_PROC 0 &mc_virt SLAVE_EBI1 0>;

			memory-region = <&cdsp_mem>;

			qcom,qmp = <&aoss_qmp>;

			qcom,smem-states = <&smp2p_cdsp_out 0>;
			qcom,smem-state-names = "stop";

			status = "disabled";

			glink-edge {
				interrupts-extended = <&ipcc IPCC_CLIENT_CDSP
							     IPCC_MPROC_SIGNAL_GLINK_QMP
							     IRQ_TYPE_EDGE_RISING>;
				mboxes = <&ipcc IPCC_CLIENT_CDSP
						IPCC_MPROC_SIGNAL_GLINK_QMP>;

				label = "cdsp";
				qcom,remote-pid = <5>;
			};
		};

		tlmm: pinctrl@f100000 {
			compatible = "qcom,qcs8300-tlmm";
			reg = <0x0 0x0f100000 0x0 0x300000>;
			interrupts = <GIC_SPI 208 IRQ_TYPE_LEVEL_HIGH>;
			gpio-controller;
			#gpio-cells = <2>;
			gpio-ranges = <&tlmm 0 0 133>;
			interrupt-controller;
			#interrupt-cells = <2>;
			wakeup-parent = <&pdc>;

			qup_uart7_default: qup-uart7-state {
				/* TX, RX */
				pins = "gpio43", "gpio44";
				function = "qup0_se7";
			};
		};

		stm@4002000 {
			compatible = "arm,coresight-stm", "arm,primecell";
			reg = <0x0 0x4002000 0x0 0x1000>,
			      <0x0 0x16280000 0x0 0x180000>;
			reg-names = "stm-base", "stm-stimulus-base";

			clocks = <&aoss_qmp>;
			clock-names = "apb_pclk";

			out-ports {
				port {
					stm_out: endpoint {
						remote-endpoint =
						<&funnel0_in7>;
					};
				};
			};
		};

		tpdm@4003000 {
			compatible = "qcom,coresight-tpdm", "arm,primecell";
			reg = <0x0 0x4003000 0x0 0x1000>;
			device-name = "tpdm_dcc";

			clocks = <&aoss_qmp>;
			clock-names = "apb_pclk";

			qcom,cmb-element-bits = <32>;
			qcom,cmb-msrs-num = <32>;
			status = "disabled";

			out-ports {
				port {
					qdss_tpdm0_out: endpoint {
						remote-endpoint =
						<&qdss_tpda_in0>;
					};
				};
			};
		};

		tpda@4004000 {
			compatible = "qcom,coresight-tpda", "arm,primecell";
			reg = <0x0 0x4004000 0x0 0x1000>;
			device-name = "tpda_qdss";

			clocks = <&aoss_qmp>;
			clock-names = "apb_pclk";

			out-ports {
				port {
					qdss_tpda_out: endpoint {
						remote-endpoint =
						<&funnel0_in6>;
					};
				};
			};

			in-ports {
				#address-cells = <1>;
				#size-cells = <0>;

				port@0 {
					reg = <0>;
					qdss_tpda_in0: endpoint {
						remote-endpoint =
						<&qdss_tpdm0_out>;
					};
				};

				port@1 {
					reg = <1>;
					qdss_tpda_in1: endpoint {
						remote-endpoint =
						<&qdss_tpdm1_out>;
					};
				};
			};
		};

		tpdm@400f000 {
			compatible = "qcom,coresight-tpdm", "arm,primecell";
			reg = <0x0 0x400f000 0x0 0x1000>;
			device-name = "tpdm_spdm";

			clocks = <&aoss_qmp>;
			clock-names = "apb_pclk";

			qcom,cmb-element-bits = <32>;
			qcom,cmb-msrs-num = <32>;

			out-ports {
				port {
					qdss_tpdm1_out: endpoint {
						remote-endpoint =
						<&qdss_tpda_in1>;
					};
				};
			};
		};

		cti@4010000 {
			compatible = "arm,coresight-cti", "arm,primecell";
			reg = <0x0 0x4010000 0x0 0x1000>;
			device-name = "cti_qdss";

			clocks = <&aoss_qmp>;
			clock-names = "apb_pclk";
			qcom,extended_cti;
		};

		funnel@4041000 {
			compatible = "arm,coresight-dynamic-funnel", "arm,primecell";
			reg = <0x0 0x4041000 0x0 0x1000>;

			clocks = <&aoss_qmp>;
			clock-names = "apb_pclk";

			out-ports {
				port {
					funnel0_out: endpoint {
						remote-endpoint =
						<&qdss_funnel_in0>;
					};
				};
			};

			in-ports {
				#address-cells = <1>;
				#size-cells = <0>;

				port@6 {
					reg = <6>;
					funnel0_in6: endpoint {
						remote-endpoint =
						<&qdss_tpda_out>;
					};
				};

				port@7 {
					reg = <7>;
					funnel0_in7: endpoint {
						remote-endpoint =
						<&stm_out>;
					};
				};
			};
		};

		funnel@4042000 {
			compatible = "arm,coresight-dynamic-funnel", "arm,primecell";
			reg = <0x0 0x4042000 0x0 0x1000>;

			clocks = <&aoss_qmp>;
			clock-names = "apb_pclk";

			out-ports {
				port {
					funnel1_out: endpoint {
						remote-endpoint =
						<&qdss_funnel_in1>;
					};
				};
			};

			in-ports {
				#address-cells = <1>;
				#size-cells = <0>;

				port@4 {
					reg = <4>;
					funnel1_in4: endpoint {
						remote-endpoint =
						<&apss_funnel1_out>;
					};
				};

				port@5 {
					reg = <5>;
					funnel1_in5: endpoint {
						remote-endpoint =
						<&dlct0_funnel_out>;
					};
				};

				port@6 {
					reg = <6>;
					funnel1_in6: endpoint {
						remote-endpoint =
						<&dlmm_funnel_out>;
					};
				};

				port@7 {
					reg = <7>;
					funnel1_in7: endpoint {
						remote-endpoint =
						<&dlst_ch_funnel_out>;
					};
				};
			};
		};

		funnel@4045000 {
			compatible = "arm,coresight-dynamic-funnel", "arm,primecell";
			reg = <0x0 0x4045000 0x0 0x1000>;

			clocks = <&aoss_qmp>;
			clock-names = "apb_pclk";

			out-ports {
				port {
					qdss_funnel_out: endpoint {
						remote-endpoint =
						<&aoss_funnel_in7>;
					};
				};
			};

			in-ports {
				#address-cells = <1>;
				#size-cells = <0>;

				port@0 {
					reg = <0>;
					qdss_funnel_in0: endpoint {
						remote-endpoint =
						<&funnel0_out>;
					};
				};

				port@1 {
					reg = <1>;
					qdss_funnel_in1: endpoint {
						remote-endpoint =
						<&funnel1_out>;
					};
				};
			};
		};

		replicator@4046000 {
			compatible = "arm,coresight-dynamic-replicator", "arm,primecell";
			reg = <0x0 0x4046000 0x0 0x1000>;

			clocks = <&aoss_qmp>;
			clock-names = "apb_pclk";

			out-ports {
				port {
					qdss_rep_out0: endpoint {
						remote-endpoint =
						<&etr_rep_in>;
					};
				};
			};

			in-ports {
				port {
					qdss_rep_in: endpoint {
						remote-endpoint =
						<&swao_rep_out0>;
					};
				};
			};
		};

		tmc_etr: tmc@4048000 {
			compatible = "arm,coresight-tmc", "arm,primecell";
			reg = <0x0 0x4048000 0x0 0x1000>;

			clocks = <&aoss_qmp>;
			clock-names = "apb_pclk";
			iommus = <&apps_smmu 0x04c0 0x00>;

			arm,scatter-gather;

			in-ports {
				port {
					etr0_in: endpoint {
						remote-endpoint =
						<&etr_rep_out0>;
					};
				};
			};
		};

		replicator@404e000 {
			compatible = "arm,coresight-dynamic-replicator", "arm,primecell";
			reg = <0x0 0x404e000 0x0 0x1000>;

			clocks = <&aoss_qmp>;
			clock-names = "apb_pclk";

			out-ports {
				#address-cells = <1>;
				#size-cells = <0>;

				port@0 {
					reg = <0>;
					etr_rep_out0: endpoint {
						remote-endpoint =
						<&etr0_in>;
					};
				};

				port@1 {
					reg = <1>;
					etr_rep_out1: endpoint {
						remote-endpoint =
						<&etr1_in>;
					};
				};
			};

			in-ports {
				port {
					etr_rep_in: endpoint {
						remote-endpoint =
						<&qdss_rep_out0>;
					};
				};
			};
		};

		tmc_etr1: tmc@404f000 {
			compatible = "arm,coresight-tmc", "arm,primecell";
			reg = <0x0 0x404f000 0x0 0x1000>;

			clocks = <&aoss_qmp>;
			clock-names = "apb_pclk";
			iommus = <&apps_smmu 0x04a0 0x40>;

			arm,scatter-gather;
			arm,buffer-size = <0x400000>;

			in-ports {
				port {
					etr1_in: endpoint {
						remote-endpoint =
						<&etr_rep_out1>;
					};
				};
			};
		};

		dma@40ff000 {
			compatible = "qcom,dcc-v2", "qcom,dcc";
			reg = <0x0 0x040ff000 0x0 0x1000>,
			      <0x0 0x040b8800 0x0 0x6000>;

			qcom,dcc-offset = <0x38800>;
		};

		tpdm@482c000 {
			compatible = "qcom,coresight-tpdm", "arm,primecell";
			reg = <0x0 0x482c000 0x0 0x1000>;
			device-name = "tpdm_gcc";

			clocks = <&aoss_qmp>;
			clock-names = "apb_pclk";

			qcom,dsb-element-bits = <32>;
			qcom,dsb-msrs-num = <32>;

			out-ports {
				port {
					gcc_tpdm_out: endpoint {
						remote-endpoint =
						<&dlct0_tpda_in20>;
					};
				};
			};
		};

		cti@4831000 {
			compatible = "arm,coresight-cti", "arm,primecell";
			reg = <0x0 0x4831000 0x0 0x1000>;
			device-name = "cti_venus";

			clocks = <&aoss_qmp>;
			clock-names = "apb_pclk";
			qcom,extended_cti;
			status = "disabled";
		};

		tpdm@4841000 {
			compatible = "qcom,coresight-tpdm", "arm,primecell";
			reg = <0x0 0x4841000 0x0 0x1000>;
			device-name = "tpdm_prng";

			clocks = <&aoss_qmp>;
			clock-names = "apb_pclk";

			qcom,cmb-element-bits = <32>;
			qcom,cmb-msrs-num = <32>;

			out-ports {
				port {
					prng_tpdm_out: endpoint {
						remote-endpoint =
						<&dlct0_tpda_in19>;
					};
				};
			};
		};

		cti@4845000 {
			compatible = "arm,coresight-cti", "arm,primecell";
			reg = <0x0 0x4845000 0x0 0x1000>;
			device-name = "cti_lpass";

			clocks = <&aoss_qmp>;
			clock-names = "apb_pclk";
			qcom,extended_cti;
		};

		tpdm@4850000 {
			compatible = "qcom,coresight-tpdm", "arm,primecell";
			reg = <0x0 0x4850000 0x0 0x1000>;
			device-name = "tpdm_pimem";

			clocks = <&aoss_qmp>;
			clock-names = "apb_pclk";

			qcom,cmb-element-bits = <64>;
			qcom,cmb-msrs-num = <32>;
			qcom,dsb-element-bits = <32>;
			qcom,dsb-msrs-num = <32>;

			out-ports {
				port {
					pimem_tpdm_out: endpoint {
						remote-endpoint =
						<&dlct0_tpda_in25>;
					};
				};
			};
		};

		tpdm@4860000 {
			compatible = "qcom,coresight-tpdm", "arm,primecell";
			reg = <0x0 0x4860000 0x0 0x1000>;
			device-name = "tpdm_dl_ch_south";

			clocks = <&aoss_qmp>;
			clock-names = "apb_pclk";

			qcom,dsb-element-bits = <32>;
			qcom,dsb-msrs-num = <32>;

			out-ports {
				port {
					dlst_ch_tpdm0_out: endpoint {
						remote-endpoint =
						<&dlst_ch_tpda_in8>;
					};
				};
			};
		};

		tpdm@4861000 {
			compatible = "qcom,coresight-tpdm", "arm,primecell";
			reg = <0x0 0x4861000 0x0 0x1000>;
			device-name = "tpdm_dl_ch_south_1";

			clocks = <&aoss_qmp>;
			clock-names = "apb_pclk";

			qcom,cmb-element-bits = <64>;
			qcom,cmb-msrs-num = <32>;
			status = "disabled";

			out-ports {
				port {
					dlst_ch_tpdm1_out: endpoint {
						remote-endpoint =
						<&dlst_ch_tpda_in9>;
					};
				};
			};
		};

		cti@4862000 {
			compatible = "arm,coresight-cti", "arm,primecell";
			reg = <0x0 0x4862000 0x0 0x1000>;
			device-name = "cti_dl_ch_south";

			clocks = <&aoss_qmp>;
			clock-names = "apb_pclk";
			qcom,extended_cti;
		};

		cti@4863000 {
			compatible = "arm,coresight-cti", "arm,primecell";
			reg = <0x0 0x4863000 0x0 0x1000>;
			device-name = "cti_dl_ch_south_1";

			clocks = <&aoss_qmp>;
			clock-names = "apb_pclk";
			qcom,extended_cti;
		};

		tpda@4864000 {
			compatible = "qcom,coresight-tpda", "arm,primecell";
			reg = <0x0 0x4864000 0x0 0x1000>;
			device-name = "tpda_dlst_ch";

			clocks = <&aoss_qmp>;
			clock-names = "apb_pclk";

			out-ports {
				port {
					dlst_ch_tpda_out: endpoint {
						remote-endpoint =
						<&dlst_ch_funnel_in0>;
					};
				};
			};

			in-ports {
				#address-cells = <1>;
				#size-cells = <0>;

				port@8 {
					reg = <8>;
					dlst_ch_tpda_in8: endpoint {
						remote-endpoint =
						<&dlst_ch_tpdm0_out>;
					};
				};

				port@9 {
					reg = <9>;
					dlst_ch_tpda_in9: endpoint {
						remote-endpoint =
						<&dlst_ch_tpdm1_out>;
					};
				};
			};
		};

		funnel@4865000 {
			compatible = "arm,coresight-dynamic-funnel", "arm,primecell";
			reg = <0x0 0x4865000 0x0 0x1000>;

			clocks = <&aoss_qmp>;
			clock-names = "apb_pclk";

			out-ports {
				port {
					dlst_ch_funnel_out: endpoint {
						remote-endpoint =
						<&funnel1_in7>;
					};
				};
			};

			in-ports {
				#address-cells = <1>;
				#size-cells = <0>;

				port@0 {
					reg = <0>;
					dlst_ch_funnel_in0: endpoint {
						remote-endpoint =
						<&dlst_ch_tpda_out>;
					};
				};

				port@4 {
					reg = <4>;
					dlst_ch_funnel_in4: endpoint {
						remote-endpoint =
						<&dlst_funnel_out>;
					};
				};

				port@6 {
					reg = <6>;
					dlst_ch_funnel_in6: endpoint {
						remote-endpoint =
						<&gdsp_funnel_out>;
					};
				};
			};
		};

		cti@4901000 {
			compatible = "arm,coresight-cti", "arm,primecell";
			reg = <0x0 0x4901000 0x0 0x1000>;
			device-name = "cti_gfx";

			clocks = <&aoss_qmp>;
			clock-names = "apb_pclk";
			qcom,extended_cti;
		};

		cti@4961000 {
			compatible = "arm,coresight-cti", "arm,primecell";
			reg = <0x0 0x4961000 0x0 0x1000>;
			device-name = "cti_gfx_1";

			clocks = <&aoss_qmp>;
			clock-names = "apb_pclk";
			status = "disabled";
		};

		cti@4962000 {
			compatible = "arm,coresight-cti", "arm,primecell";
			reg = <0x0 0x4962000 0x0 0x1000>;
			device-name = "cti_gfx_2";

			clocks = <&aoss_qmp>;
			clock-names = "apb_pclk";
			status = "disabled";
		};

		tpdm@4980000 {
			compatible = "qcom,coresight-tpdm", "arm,primecell";
			reg = <0x0 0x4980000 0x0 0x1000>;
			device-name = "tpdm_turing";

			clocks = <&aoss_qmp>;
			clock-names = "apb_pclk";

			qcom,dsb-element-bits = <32>;
			qcom,dsb-msrs-num = <32>;

			out-ports {
				port {
					turing2_tpdm_out: endpoint {
						remote-endpoint =
						<&turing2_funnel_in0>;
					};
				};
			};
		};

		cti@4982000 {
			compatible = "arm,coresight-cti", "arm,primecell";
			reg = <0x0 0x4982000 0x0 0x1000>;
			device-name = "cti_turing";

			clocks = <&aoss_qmp>;
			clock-names = "apb_pclk";
			qcom,extended_cti;
		};

		funnel@4983000 {
			compatible = "arm,coresight-dynamic-funnel", "arm,primecell";
			reg = <0x0 0x4983000 0x0 0x1000>;

			clocks = <&aoss_qmp>;
			clock-names = "apb_pclk";

			out-ports {
				port {
					turing2_funnel_out0: endpoint {
						remote-endpoint =
						<&gdsp_tpda_in5>;
					};
				};
			};

			in-ports {
				#address-cells = <1>;
				#size-cells = <0>;

				port@0 {
					reg = <0>;
					turing2_funnel_in0: endpoint {
						remote-endpoint =
						<&turing2_tpdm_out>;
					};
				};
			};
		};

		tpdm@49ca000 {
			compatible = "qcom,coresight-tpdm", "arm,primecell";
			reg = <0x0 0x49ca000 0x0 0x1000>;
			device-name = "tpdm_sdcc_1";

			clocks = <&aoss_qmp>;
			clock-names = "apb_pclk";

			qcom,cmb-element-bits = <32>;
			qcom,cmb-msrs-num = <32>;
			status = "disabled";

			out-ports {
				port {
					sdcc_tpdm_out: endpoint {
						remote-endpoint =
						<&dlst_tpda_in1>;
					};
				};
			};
		};

		tpdm@49c0000 {
			compatible = "qcom,coresight-tpdm", "arm,primecell";
			reg = <0x0 0x49c0000 0x0 0x1000>;
			device-name = "tpdm_rdpm_mxa";

			clocks = <&aoss_qmp>;
			clock-names = "apb_pclk";

			qcom,cmb-element-bits = <64>;
			qcom,cmb-msrs-num = <32>;
			status = "disabled";

			out-ports {
				port {
					rdpm_tpdm_out: endpoint {
						remote-endpoint =
						<&dlct0_tpda_in23>;
					};
				};
			};
		};

		tpdm@49d0000 {
			compatible = "qcom,coresight-tpdm", "arm,primecell";
			reg = <0x0 0x49d0000 0x0 0x1000>;
			device-name = "tpdm_qm";

			clocks = <&aoss_qmp>;
			clock-names = "apb_pclk";

			qcom,dsb-element-bits = <32>;
			qcom,dsb-msrs-num = <32>;

			out-ports {
				port {
					qm_tpdm_out: endpoint {
						remote-endpoint =
						<&dlct0_tpda_in21>;
					};
				};
			};
		};

		tpdm@4ac0000 {
			compatible = "qcom,coresight-tpdm", "arm,primecell";
			reg = <0x0 0x4ac0000 0x0 0x1000>;
			device-name = "tpdm_mmnoc_0";

			clocks = <&aoss_qmp>;
			clock-names = "apb_pclk";

			qcom,dsb-element-bits = <32>;
			qcom,dsb-msrs-num = <32>;

			out-ports {
				port {
					dlmm_tpdm0_out: endpoint {
						remote-endpoint =
						<&dlmm_tpda_in27>;
					};
				};
			};
		};

		tpdm@4ac1000 {
			compatible = "qcom,coresight-tpdm", "arm,primecell";
			reg = <0x0 0x4ac1000 0x0 0x1000>;
			device-name = "tpdm_mmnoc_1";

			clocks = <&aoss_qmp>;
			clock-names = "apb_pclk";

			qcom,cmb-element-bits = <64>;
			qcom,cmb-msrs-num = <32>;
			status = "disabled";

			out-ports {
				port {
					dlmm_tpdm1_out: endpoint {
						remote-endpoint =
						<&dlmm_tpda_in28>;
					};
				};
			};
		};

		cti@4ac2000 {
			compatible = "arm,coresight-cti", "arm,primecell";
			reg = <0x0 0x4ac2000 0x0 0x1000>;
			device-name = "cti_mmnoc_0";

			clocks = <&aoss_qmp>;
			clock-names = "apb_pclk";
			qcom,extended_cti;
		};

		cti@4ac3000 {
			compatible = "arm,coresight-cti", "arm,primecell";
			reg = <0x0 0x4ac3000 0x0 0x1000>;
			device-name = "cti_mmnoc_1";

			clocks = <&aoss_qmp>;
			clock-names = "apb_pclk";
			qcom,extended_cti;
		};

		tpda@4ac4000 {
			compatible = "qcom,coresight-tpda", "arm,primecell";
			reg = <0x0 0x4ac4000 0x0 0x1000>;
			device-name = "tpda_dlmm";

			clocks = <&aoss_qmp>;
			clock-names = "apb_pclk";

			out-ports {
				port {
					dlmm_tpda_out: endpoint {
						remote-endpoint =
						<&dlmm_funnel_in0>;
					};
				};
			};

			in-ports {
				#address-cells = <1>;
				#size-cells = <0>;

				port@8 {
					reg = <8>;
					dlmm_tpda_in8: endpoint {
						remote-endpoint =
						<&mdss1_tpdm_out>;
					};
				};

				port@1b {
					reg = <27>;
					dlmm_tpda_in27: endpoint {
						remote-endpoint =
						<&dlmm_tpdm0_out>;
					};
				};

				port@1c {
					reg = <28>;
					dlmm_tpda_in28: endpoint {
						remote-endpoint =
						<&dlmm_tpdm1_out>;
					};
				};
			};
		};

		funnel@4ac5000 {
			compatible = "arm,coresight-dynamic-funnel", "arm,primecell";
			reg = <0x0 0x4ac5000 0x0 0x1000>;

			clocks = <&aoss_qmp>;
			clock-names = "apb_pclk";

			out-ports {
				port {
					dlmm_funnel_out: endpoint {
						remote-endpoint =
						<&funnel1_in6>;
					};
				};
			};

			in-ports {
				#address-cells = <1>;
				#size-cells = <0>;

				port@0 {
					reg = <0>;
					dlmm_funnel_in0: endpoint {
						remote-endpoint =
						<&dlmm_tpda_out>;
					};
				};
			};
		};

		tpdm@4ad0000 {
			compatible = "qcom,coresight-tpdm", "arm,primecell";
			reg = <0x0 0x4ad0000 0x0 0x1000>;
			device-name = "tpdm_dlct";

			clocks = <&aoss_qmp>;
			clock-names = "apb_pclk";

			qcom,dsb-element-bits = <32>;
			qcom,dsb-msrs-num = <32>;

			out-ports {
				port {
					dlct0_tpdm0_out: endpoint {
						remote-endpoint =
						<&dlct0_tpda_in26>;
					};
				};
			};
		};

		tpdm@4ad1000 {
			compatible = "qcom,coresight-tpdm", "arm,primecell";
			reg = <0x0 0x4ad1000 0x0 0x1000>;
			device-name = "tpdm_ipcc";

			clocks = <&aoss_qmp>;
			clock-names = "apb_pclk";

			qcom,cmb-element-bits = <64>;
			qcom,cmb-msrs-num = <32>;
			status = "disabled";

			out-ports {
				port {
					dlct0_tpdm1_out: endpoint {
						remote-endpoint =
						<&dlct0_tpda_in27>;
					};
				};
			};
		};

		cti@4ad2000 {
			compatible = "arm,coresight-cti", "arm,primecell";
			reg = <0x0 0x4ad2000 0x0 0x1000>;
			device-name = "cti_dlct";

			clocks = <&aoss_qmp>;
			clock-names = "apb_pclk";
			qcom,extended_cti;
		};

		tpda@4ad3000 {
			compatible = "qcom,coresight-tpda", "arm,primecell";
			reg = <0x0 0x4ad3000 0x0 0x1000>;
			device-name = "tpda_dlct0";

			clocks = <&aoss_qmp>;
			clock-names = "apb_pclk";

			out-ports {
				port {
					dlct0_tpda_out: endpoint {
						remote-endpoint =
						<&dlct0_funnel_in0>;
					};
				};
			};

			in-ports {
				#address-cells = <1>;
				#size-cells = <0>;

				port@13 {
					reg = <19>;
					dlct0_tpda_in19: endpoint {
						remote-endpoint =
						<&prng_tpdm_out>;
					};
				};

				port@14 {
					reg = <20>;
					dlct0_tpda_in20: endpoint {
						remote-endpoint =
						<&gcc_tpdm_out>;
					};
				};

				port@15 {
					reg = <21>;
					dlct0_tpda_in21: endpoint {
						remote-endpoint =
						<&qm_tpdm_out>;
					};
				};

				port@17 {
					reg = <23>;
					dlct0_tpda_in23: endpoint {
						remote-endpoint =
						<&rdpm_tpdm_out>;
					};
				};

				port@19 {
					reg = <25>;
					dlct0_tpda_in25: endpoint {
						remote-endpoint =
						<&pimem_tpdm_out>;
					};
				};

				port@1a {
					reg = <26>;
					dlct0_tpda_in26: endpoint {
						remote-endpoint =
						<&dlct0_tpdm0_out>;
					};
				};

				port@1b {
					reg = <27>;
					dlct0_tpda_in27: endpoint {
						remote-endpoint =
						<&dlct0_tpdm1_out>;
					};
				};
			};
		};

		funnel@4ad4000 {
			compatible = "arm,coresight-dynamic-funnel", "arm,primecell";
			reg = <0x0 0x4ad4000 0x0 0x1000>;

			clocks = <&aoss_qmp>;
			clock-names = "apb_pclk";

			out-ports {
				port {
					dlct0_funnel_out: endpoint {
						remote-endpoint =
						<&funnel1_in5>;
					};
				};
			};

			in-ports {
				#address-cells = <1>;
				#size-cells = <0>;

				port@0 {
					reg = <0>;
					dlct0_funnel_in0: endpoint {
						remote-endpoint =
						<&dlct0_tpda_out>;
					};
				};

				port@4 {
					reg = <4>;
					dlct0_funnel_in4: endpoint {
						remote-endpoint =
						<&ddr_funnel5_out>;
					};
				};
			};
		};

		cti@4b00000 {
			compatible = "arm,coresight-cti", "arm,primecell";
			reg = <0x0 0x4b00000 0x0 0x1000>;
			device-name = "cti_swao";

			clocks = <&aoss_qmp>;
			clock-names = "apb_pclk";
			qcom,extended_cti;
		};

		funnel@4b04000 {
			compatible = "arm,coresight-dynamic-funnel", "arm,primecell";
			reg = <0x0 0x4b04000 0x0 0x1000>;

			clocks = <&aoss_qmp>;
			clock-names = "apb_pclk";

			out-ports {
				port {
					aoss_funnel_out: endpoint {
						remote-endpoint =
						<&etf0_in>;
					};
				};
			};

			in-ports {
				#address-cells = <1>;
				#size-cells = <0>;

				port@5 {
					reg = <5>;
					aoss_funnel_in5: endpoint {
						remote-endpoint =
						<&lpi_funnel_out>;
					};
				};

				port@6 {
					reg = <6>;
					aoss_funnel_in6: endpoint {
						remote-endpoint =
						<&aoss_tpda_out>;
					};
				};

				port@7 {
					reg = <7>;
					aoss_funnel_in7: endpoint {
						remote-endpoint =
						<&qdss_funnel_out>;
					};
				};
			};
		};

		tmc_etf: tmc@4b05000 {
			compatible = "arm,coresight-tmc", "arm,primecell";
			reg = <0x0 0x4b05000 0x0 0x1000>;

			clocks = <&aoss_qmp>;
			clock-names = "apb_pclk";

			out-ports {
				port {
					etf0_out: endpoint {
						remote-endpoint =
						<&swao_rep_in>;
					};
				};
			};

			in-ports {
				port {
					etf0_in: endpoint {
						remote-endpoint =
						<&aoss_funnel_out>;
					};
				};
			};
		};

		replicator@4b06000 {
			compatible = "arm,coresight-dynamic-replicator", "arm,primecell";
			reg = <0x0 0x4b06000 0x0 0x1000>;

			clocks = <&aoss_qmp>;
			clock-names = "apb_pclk";

			out-ports {
				#address-cells = <1>;
				#size-cells = <0>;

				port@0 {
					reg = <0>;
					swao_rep_out0: endpoint {
						remote-endpoint =
						<&qdss_rep_in>;
					};
				};

				port@1 {
					reg = <1>;
					swao_rep_out1: endpoint {
						remote-endpoint =
						<&eud_in>;
					};
				};
			};

			in-ports {
				port {
					swao_rep_in: endpoint {
						remote-endpoint =
						<&etf0_out>;
					};
				};
			};
		};

		tpda@4b08000 {
			compatible = "qcom,coresight-tpda", "arm,primecell";
			reg = <0x0 0x4b08000 0x0 0x1000>;
			device-name = "tpda_aoss";

			clocks = <&aoss_qmp>;
			clock-names = "apb_pclk";

			out-ports {
				port {
					aoss_tpda_out: endpoint {
						remote-endpoint =
						<&aoss_funnel_in6>;
					};
				};
			};

			in-ports {
				#address-cells = <1>;
				#size-cells = <0>;

				port@0 {
					reg = <0>;
					aoss_tpda_in0: endpoint {
						remote-endpoint =
						<&aoss_tpdm0_out>;
					};
				};

				port@1 {
					reg = <1>;
					aoss_tpda_in1: endpoint {
						remote-endpoint =
						<&aoss_tpdm1_out>;
					};
				};

				port@2 {
					reg = <2>;
					aoss_tpda_in2: endpoint {
						remote-endpoint =
						<&aoss_tpdm2_out>;
					};
				};

				port@3 {
					reg = <3>;
					aoss_tpda_in3: endpoint {
						remote-endpoint =
						<&aoss_tpdm3_out>;
					};
				};

				port@4 {
					reg = <4>;
					aoss_tpda_in4: endpoint {
						remote-endpoint =
						<&aoss_tpdm4_out>;
					};
				};
			};
		};

		tpdm@4b09000 {
			compatible = "qcom,coresight-tpdm", "arm,primecell";
			reg = <0x0 0x4b09000 0x0 0x1000>;
			device-name = "tpdm_swao_prio_0";

			clocks = <&aoss_qmp>;
			clock-names = "apb_pclk";

			qcom,cmb-element-bits = <64>;
			qcom,cmb-msrs-num = <32>;

			out-ports {
				port {
					aoss_tpdm0_out: endpoint {
						remote-endpoint =
						<&aoss_tpda_in0>;
					};
				};
			};
		};

		tpdm@4b0a000 {
			compatible = "qcom,coresight-tpdm", "arm,primecell";
			reg = <0x0 0x4b0a000 0x0 0x1000>;
			device-name = "tpdm_swao_prio_1";

			clocks = <&aoss_qmp>;
			clock-names = "apb_pclk";

			qcom,cmb-element-bits = <64>;
			qcom,cmb-msrs-num = <32>;

			out-ports {
				port {
					aoss_tpdm1_out: endpoint {
						remote-endpoint =
						<&aoss_tpda_in1>;
					};
				};
			};
		};

		tpdm@4b0b000 {
			compatible = "qcom,coresight-tpdm", "arm,primecell";
			reg = <0x0 0x4b0b000 0x0 0x1000>;
			device-name = "tpdm_swao_prio_2";

			clocks = <&aoss_qmp>;
			clock-names = "apb_pclk";

			qcom,cmb-element-bits = <64>;
			qcom,cmb-msrs-num = <32>;

			out-ports {
				port {
					aoss_tpdm2_out: endpoint {
						remote-endpoint =
						<&aoss_tpda_in2>;
					};
				};
			};
		};

		tpdm@4b0c000 {
			compatible = "qcom,coresight-tpdm", "arm,primecell";
			reg = <0x0 0x4b0c000 0x0 0x1000>;
			device-name = "tpdm_swao_prio_3";

			clocks = <&aoss_qmp>;
			clock-names = "apb_pclk";

			qcom,cmb-element-bits = <64>;
			qcom,cmb-msrs-num = <32>;

			out-ports {
				port {
					aoss_tpdm3_out: endpoint {
						remote-endpoint =
						<&aoss_tpda_in3>;
					};
				};
			};
		};

		tpdm@4b0d000 {
			compatible = "qcom,coresight-tpdm", "arm,primecell";
			reg = <0x0 0x4b0d000 0x0 0x1000>;
			device-name = "tpdm_swao_1";

			clocks = <&aoss_qmp>;
			clock-names = "apb_pclk";

			qcom,dsb-element-bits = <32>;
			qcom,dsb-msrs-num = <32>;

			out-ports {
				port {
					aoss_tpdm4_out: endpoint {
						remote-endpoint =
						<&aoss_tpda_in4>;
					};
				};
			};
		};

		cti@4b13000 {
			compatible = "arm,coresight-cti", "arm,primecell";
			reg = <0x0 0x4b13000 0x0 0x1000>;
			device-name = "cti_aoss";

			clocks = <&aoss_qmp>;
			clock-names = "apb_pclk";
		};

		cti@4b41000 {
			compatible = "arm,coresight-cti", "arm,primecell";
			reg = <0x0 0x4b41000 0x0 0x1000>;
			device-name = "cti_lpass_core";

			clocks = <&aoss_qmp>;
			clock-names = "apb_pclk";
			status = "disabled";
		};

		tpdm@4b46000 {
			compatible = "qcom,coresight-tpdm", "arm,primecell";
			reg = <0x0 0x4b46000 0x0 0x1000>;
			device-name = "tpdm_lpass_lpi";

			clocks = <&aoss_qmp>;
			clock-names = "apb_pclk";

			qcom,dsb-element-bits = <32>;
			qcom,dsb-msrs-num = <32>;
			status = "disabled";

			out-ports {
				port {
					lpi_tpdm_out: endpoint {
						remote-endpoint =
						<&lpi_tpda_in>;
					};
				};
			};
		};

		tpda@4b47000 {
			compatible = "qcom,coresight-tpda", "arm,primecell";
			reg = <0x0 0x4b47000 0x0 0x1000>;
			device-name = "tpda_lpi";

			clocks = <&aoss_qmp>;
			clock-names = "apb_pclk";
			status = "disabled";

			out-ports {
				port {
					lpi_tpda_out: endpoint {
						remote-endpoint =
						<&lpi_funnel_in5>;
					};
				};
			};

			in-ports {
				port {
					lpi_tpda_in: endpoint {
						remote-endpoint =
						<&lpi_tpdm_out>;
					};
				};
			};
		};

		cti@4b4b000 {
			compatible = "arm,coresight-cti", "arm,primecell";
			reg = <0x0 0x4b4b000 0x0 0x1000>;
			device-name = "cti_lpass_lpi";

			clocks = <&aoss_qmp>;
			clock-names = "apb_pclk";
			status = "disabled";
		};

		tpdm@4b80000 {
			compatible = "qcom,coresight-tpdm", "arm,primecell";
			reg = <0x0 0x4b80000 0x0 0x1000>;
			device-name = "tpdm_turing_0";

			clocks = <&aoss_qmp>;
			clock-names = "apb_pclk";

			qcom,dsb-element-bits = <32>;
			qcom,dsb-msrs-num = <32>;

			out-ports {
				port {
					turing0_tpdm0_out: endpoint {
						remote-endpoint =
						<&turing0_tpda_in0>;
					};
				};
			};
		};

		tpdm@4b81000 {
			compatible = "qcom,coresight-tpdm", "arm,primecell";
			reg = <0x0 0x4b81000 0x0 0x1000>;
			device-name = "tpdm_turing_llm_0";

			clocks = <&aoss_qmp>;
			clock-names = "apb_pclk";

			qcom,cmb-element-bits = <32>;
			qcom,cmb-msrs-num = <32>;
			status = "disabled";

			out-ports {
				port {
					turing0_tpdm1_out: endpoint {
						remote-endpoint =
						<&turing0_tpda_in1>;
					};
				};
			};
		};

		tpdm@4b82000 {
			compatible = "qcom,coresight-tpdm", "arm,primecell";
			reg = <0x0 0x4b82000 0x0 0x1000>;
			device-name = "tpdm_turing_llm_1";

			clocks = <&aoss_qmp>;
			clock-names = "apb_pclk";

			qcom,cmb-element-bits = <32>;
			qcom,cmb-msrs-num = <32>;
			status = "disabled";

			out-ports {
				port {
					turing0_tpdm2_out: endpoint {
						remote-endpoint =
						<&turing0_tpda_in2>;
					};
				};
			};
		};

		tpdm@4b83000 {
			compatible = "qcom,coresight-tpdm", "arm,primecell";
			reg = <0x0 0x4b83000 0x0 0x1000>;
			device-name = "tpdm_turing_llm_2";

			clocks = <&aoss_qmp>;
			clock-names = "apb_pclk";

			qcom,cmb-element-bits = <64>;
			qcom,cmb-msrs-num = <32>;
			status = "disabled";

			out-ports {
				port {
					turing0_tpdm3_out: endpoint {
						remote-endpoint =
						<&turing0_tpda_in3>;
					};
				};
			};
		};

		tpdm@4b84000 {
			compatible = "qcom,coresight-tpdm", "arm,primecell";
			reg = <0x0 0x4b84000 0x0 0x1000>;
			device-name = "tpdm_turing_llm_3";

			clocks = <&aoss_qmp>;
			clock-names = "apb_pclk";

			qcom,cmb-element-bits = <64>;
			qcom,cmb-msrs-num = <32>;
			status = "disabled";

			out-ports {
				port {
					turing0_tpdm4_out: endpoint {
						remote-endpoint =
						<&turing0_tpda_in4>;
					};
				};
			};
		};

		cti@4b85000 {
			compatible = "arm,coresight-cti", "arm,primecell";
			reg = <0x0 0x4b85000 0x0 0x1000>;
			device-name = "cti_turing_llm";

			clocks = <&aoss_qmp>;
			clock-names = "apb_pclk";
			qcom,extended_cti;
		};

		tpda@4b86000 {
			compatible = "qcom,coresight-tpda", "arm,primecell";
			reg = <0x0 0x4b86000 0x0 0x1000>;
			device-name = "tpda_turing0";

			clocks = <&aoss_qmp>;
			clock-names = "apb_pclk";

			out-ports {
				port {
					turing0_tpda_out: endpoint {
						remote-endpoint =
						<&turing0_funnel_in0>;
					};
				};
			};

			in-ports {
				#address-cells = <1>;
				#size-cells = <0>;

				port@0 {
					reg = <0>;
					turing0_tpda_in0: endpoint {
						remote-endpoint =
						<&turing0_tpdm0_out>;
					};
				};

				port@1 {
					reg = <1>;
					turing0_tpda_in1: endpoint {
						remote-endpoint =
						<&turing0_tpdm1_out>;
					};
				};

				port@2 {
					reg = <2>;
					turing0_tpda_in2: endpoint {
						remote-endpoint =
						<&turing0_tpdm2_out>;
					};
				};

				port@3 {
					reg = <3>;
					turing0_tpda_in3: endpoint {
						remote-endpoint =
						<&turing0_tpdm3_out>;
					};
				};

				port@4 {
					reg = <4>;
					turing0_tpda_in4: endpoint {
						remote-endpoint =
						<&turing0_tpdm4_out>;
					};
				};
			};
		};

		funnel@4b87000 {
			compatible = "arm,coresight-dynamic-funnel", "arm,primecell";
			reg = <0x0 0x4b87000 0x0 0x1000>;

			clocks = <&aoss_qmp>;
			clock-names = "apb_pclk";

			out-ports {
				port {
					turing0_funnel_out: endpoint {
						remote-endpoint =
						<&gdsp_funnel_in4>;
					};
				};
			};

			in-ports {
				#address-cells = <1>;
				#size-cells = <0>;

				port@0 {
					reg = <0>;
					turing0_funnel_in0: endpoint {
						remote-endpoint =
						<&turing0_tpda_out>;
					};
				};

				port@3 {
					reg = <3>;
					turing0_funnel_in3: endpoint {
						remote-endpoint =
						<&turing0_etm0_out>;
					};
				};
			};
		};

		cti@4b8b000 {
			compatible = "arm,coresight-cti", "arm,primecell";
			reg = <0x0 0x4b8b000 0x0 0x1000>;
			device-name = "cti_turing_1";

			clocks = <&aoss_qmp>;
			clock-names = "apb_pclk";
		};

		tpdm@4c40000 {
			compatible = "qcom,coresight-tpdm", "arm,primecell";
			reg = <0x0 0x4c40000 0x0 0x1000>;
			device-name = "tpdm_gpdsp_0";

			clocks = <&aoss_qmp>;
			clock-names = "apb_pclk";

			qcom,dsb-element-bits = <32>;
			qcom,dsb-msrs-num = <32>;

			out-ports {
				port {
					gdsp_tpdm0_out: endpoint {
						remote-endpoint =
						<&gdsp_tpda_in8>;
					};
				};
			};
		};

		tpdm@4c41000 {
			compatible = "qcom,coresight-tpdm", "arm,primecell";
			reg = <0x0 0x4c41000 0x0 0x1000>;
			device-name = "tpdm_gpdsp_1";

			clocks = <&aoss_qmp>;
			clock-names = "apb_pclk";

			qcom,cmb-element-bits = <64>;
			qcom,cmb-msrs-num = <32>;
			status = "disabled";

			out-ports {
				port {
					gdsp_tpdm1_out: endpoint {
						remote-endpoint =
						<&gdsp_tpda_in9>;
					};
				};
			};
		};

		cti@4c42000 {
			compatible = "arm,coresight-cti", "arm,primecell";
			reg = <0x0 0x4c42000 0x0 0x1000>;
			device-name = "cti_gpdsp_0";

			clocks = <&aoss_qmp>;
			clock-names = "apb_pclk";
			qcom,extended_cti;
		};

		cti@4c43000 {
			compatible = "arm,coresight-cti", "arm,primecell";
			reg = <0x0 0x4c43000 0x0 0x1000>;
			device-name = "cti_gpdsp_1";

			clocks = <&aoss_qmp>;
			clock-names = "apb_pclk";
			qcom,extended_cti;
		};

		tpda@4c44000 {
			compatible = "qcom,coresight-tpda", "arm,primecell";
			reg = <0x0 0x4c44000 0x0 0x1000>;
			device-name = "tpda_gpdsp";

			clocks = <&aoss_qmp>;
			clock-names = "apb_pclk";

			out-ports {
				port {
					gdsp_tpda_out: endpoint {
						remote-endpoint =
						<&gdsp_funnel_in0>;
					};
				};
			};

			in-ports {
				#address-cells = <1>;
				#size-cells = <0>;

				port@5 {
					reg = <5>;
					gdsp_tpda_in5: endpoint {
						remote-endpoint =
						<&turing2_funnel_out0>;
					};
				};

				port@8 {
					reg = <8>;
					gdsp_tpda_in8: endpoint {
						remote-endpoint =
						<&gdsp_tpdm0_out>;
					};
				};

				port@9 {
					reg = <9>;
					gdsp_tpda_in9: endpoint {
						remote-endpoint =
						<&gdsp_tpdm1_out>;
					};
				};
			};
		};

		funnel@4c45000 {
			compatible = "arm,coresight-dynamic-funnel", "arm,primecell";
			reg = <0x0 0x4c45000 0x0 0x1000>;

			clocks = <&aoss_qmp>;
			clock-names = "apb_pclk";

			out-ports {
				port {
					gdsp_funnel_out: endpoint {
						remote-endpoint =
						<&dlst_ch_funnel_in6>;
					};
				};
			};

			in-ports {
				#address-cells = <1>;
				#size-cells = <0>;

				port@0 {
					reg = <0>;
					gdsp_funnel_in0: endpoint {
						remote-endpoint =
						<&gdsp_tpda_out>;
					};
				};

				port@4 {
					reg = <4>;
					gdsp_funnel_in4: endpoint {
						remote-endpoint =
						<&turing0_funnel_out>;
					};
				};
			};
		};

		tpdm@4c50000 {
			compatible = "qcom,coresight-tpdm", "arm,primecell";
			reg = <0x0 0x4c50000 0x0 0x1000>;
			device-name = "tpdm_dl_south";

			clocks = <&aoss_qmp>;
			clock-names = "apb_pclk";

			qcom,dsb-element-bits = <32>;
			qcom,dsb-msrs-num = <32>;

			out-ports {
				port {
					dlst_tpdm0_out: endpoint {
						remote-endpoint =
						<&dlst_tpda_in8>;
					};
				};
			};
		};

		tpdm@4c51000 {
			compatible = "qcom,coresight-tpdm", "arm,primecell";
			reg = <0x0 0x4c51000 0x0 0x1000>;
			device-name = "tpdm_dl_south_1";

			clocks = <&aoss_qmp>;
			clock-names = "apb_pclk";

			qcom,cmb-element-bits = <64>;
			qcom,cmb-msrs-num = <32>;
			status = "disabled";

			out-ports {
				port {
					dlst_tpdm1_out: endpoint {
						remote-endpoint =
						<&dlst_tpda_in9>;
					};
				};
			};
		};

		cti@4c52000 {
			compatible = "arm,coresight-cti", "arm,primecell";
			reg = <0x0 0x4c52000 0x0 0x1000>;
			device-name = "cti_dl_south";

			clocks = <&aoss_qmp>;
			clock-names = "apb_pclk";
			qcom,extended_cti;
		};

		cti@4c53000 {
			compatible = "arm,coresight-cti", "arm,primecell";
			reg = <0x0 0x4c53000 0x0 0x1000>;
			device-name = "cti_dl_south_1";

			clocks = <&aoss_qmp>;
			clock-names = "apb_pclk";
			qcom,extended_cti;
		};

		tpda@4c54000 {
			compatible = "qcom,coresight-tpda", "arm,primecell";
			reg = <0x0 0x4c54000 0x0 0x1000>;
			device-name = "tpda_dlst";

			clocks = <&aoss_qmp>;
			clock-names = "apb_pclk";

			out-ports {
				port {
					dlst_tpda_out: endpoint {
						remote-endpoint =
						<&dlst_funnel_in0>;
					};
				};
			};

			in-ports {
				#address-cells = <1>;
				#size-cells = <0>;

				port@1 {
					reg = <1>;
					dlst_tpda_in1: endpoint {
						remote-endpoint =
						<&sdcc_tpdm_out>;
					};
				};

				port@8 {
					reg = <8>;
					dlst_tpda_in8: endpoint {
						remote-endpoint =
						<&dlst_tpdm0_out>;
					};
				};

				port@9 {
					reg = <9>;
					dlst_tpda_in9: endpoint {
						remote-endpoint =
						<&dlst_tpdm1_out>;
					};
				};
			};
		};

		funnel@4c55000 {
			compatible = "arm,coresight-dynamic-funnel", "arm,primecell";
			reg = <0x0 0x4c55000 0x0 0x1000>;

			clocks = <&aoss_qmp>;
			clock-names = "apb_pclk";

			out-ports {
				port {
					dlst_funnel_out: endpoint {
						remote-endpoint =
						<&dlst_ch_funnel_in4>;
					};
				};
			};

			in-ports {
				#address-cells = <1>;
				#size-cells = <0>;

				port@0 {
					reg = <0>;
					dlst_funnel_in0: endpoint {
						remote-endpoint =
						<&dlst_tpda_out>;
					};
				};
			};
		};

		tpdm@4c70000 {
			compatible = "qcom,coresight-tpdm", "arm,primecell";
			reg = <0x0 0x4c70000 0x0 0x1000>;
			device-name = "tpdm_mdss_1";

			clocks = <&aoss_qmp>;
			clock-names = "apb_pclk";

			qcom,dsb-element-bits = <32>;
			qcom,dsb-msrs-num = <32>;
			qcom,cmb-element-bits = <32>;
			qcom,cmb-msrs-num = <32>;
			status = "disabled";

			out-ports {
				port {
					mdss1_tpdm_out: endpoint {
						remote-endpoint =
						<&dlmm_tpda_in8>;
					};
				};
			};
		};

		cti@4c71000 {
			compatible = "arm,coresight-cti", "arm,primecell";
			reg = <0x0 0x4c71000 0x0 0x1000>;
			device-name = "cti_mdss_1";

			clocks = <&aoss_qmp>;
			clock-names = "apb_pclk";
			qcom,extended_cti;
			status = "disabled";
		};

		tpdm@4e00000 {
			compatible = "qcom,coresight-tpdm", "arm,primecell";
			reg = <0x0 0x4e00000 0x0 0x1000>;
			device-name = "tpdm_ddr";

			clocks = <&aoss_qmp>;
			clock-names = "apb_pclk";

			qcom,dsb-element-bits = <32>;
			qcom,dsb-msrs-num = <32>;
			qcom,cmb-element-bits = <32>;
			qcom,cmb-msrs-num = <32>;

			out-ports {
				port {
					ddr_tpdm3_out: endpoint {
						remote-endpoint =
						<&ddr_tpda_in4>;
					};
				};
			};
		};

		tpdm@4e01000 {
			compatible = "qcom,coresight-tpdm", "arm,primecell";
			reg = <0x0 0x4e01000 0x0 0x1000>;
			device-name = "tpdm_shrm";

			clocks = <&aoss_qmp>;
			clock-names = "apb_pclk";

			qcom,cmb-element-bits = <64>;
			qcom,cmb-msrs-num = <32>;
			status = "disabled";

			out-ports {
				port {
					ddr_tpdm4_out: endpoint {
						remote-endpoint =
						<&ddr_tpda_in5>;
					};
				};
			};
		};

		cti@4e02000 {
			compatible = "arm,coresight-cti", "arm,primecell";
			reg = <0x0 0x4e02000 0x0 0x1000>;
			device-name = "cti_ddr";

			clocks = <&aoss_qmp>;
			clock-names = "apb_pclk";
			qcom,extended_cti;
		};

		tpda@4e03000 {
			compatible = "qcom,coresight-tpda", "arm,primecell";
			reg = <0x0 0x4e03000 0x0 0x1000>;
			device-name = "tpda_ddr";

			clocks = <&aoss_qmp>;
			clock-names = "apb_pclk";

			out-ports {
				port {
					ddr_tpda_out: endpoint {
						remote-endpoint =
						<&ddr_funnel5_in0>;
					};
				};
			};

			in-ports {
				#address-cells = <1>;
				#size-cells = <0>;

				port@0 {
					reg = <0>;
					ddr_tpda_in0: endpoint {
						remote-endpoint =
						<&ddr_funnel0_out0>;
					};
				};

				port@1 {
					reg = <1>;
					ddr_tpda_in1: endpoint {
						remote-endpoint =
						<&ddr_funnel1_out0>;
					};
				};

				port@4 {
					reg = <4>;
					ddr_tpda_in4: endpoint {
						remote-endpoint =
						<&ddr_tpdm3_out>;
					};
				};

				port@5 {
					reg = <5>;
					ddr_tpda_in5: endpoint {
						remote-endpoint =
						<&ddr_tpdm4_out>;
					};
				};
			};
		};

		funnel@4e04000 {
			compatible = "arm,coresight-dynamic-funnel", "arm,primecell";
			reg = <0x0 0x4e04000 0x0 0x1000>;

			clocks = <&aoss_qmp>;
			clock-names = "apb_pclk";

			out-ports {
				port {
					ddr_funnel5_out: endpoint {
						remote-endpoint =
						<&dlct0_funnel_in4>;
					};
				};
			};

			in-ports {
				#address-cells = <1>;
				#size-cells = <0>;

				port@0 {
					reg = <0>;
					ddr_funnel5_in0: endpoint {
						remote-endpoint =
						<&ddr_tpda_out>;
					};
				};
			};
		};

		cti@4e0c000 {
			compatible = "arm,coresight-cti", "arm,primecell";
			reg = <0x0 0x4e0c000 0x0 0x1000>;
			device-name = "cti_ddr_1";

			clocks = <&aoss_qmp>;
			clock-names = "apb_pclk";
			qcom,extended_cti;
		};

		tpdm@4e10000 {
			compatible = "qcom,coresight-tpdm", "arm,primecell";
			reg = <0x0 0x4e10000 0x0 0x1000>;
			device-name = "tpdm_ddr_ch0";

			clocks = <&aoss_qmp>;
			clock-names = "apb_pclk";

			qcom,dsb-element-bits = <32>;
			qcom,dsb-msrs-num = <32>;

			out-ports {
				port {
					ddr_tpdm0_out: endpoint {
						remote-endpoint =
						<&ddr_funnel0_in0>;
					};
				};
			};
		};

		cti@4e11000 {
			compatible = "arm,coresight-cti", "arm,primecell";
			reg = <0x0 0x4e11000 0x0 0x1000>;
			device-name = "cti_ddr_ch0";

			clocks = <&aoss_qmp>;
			clock-names = "apb_pclk";
			qcom,extended_cti;
		};

		funnel@4e12000 {
			compatible = "arm,coresight-dynamic-funnel", "arm,primecell";
			reg = <0x0 0x4e12000 0x0 0x1000>;

			clocks = <&aoss_qmp>;
			clock-names = "apb_pclk";

			out-ports {
				port {
					ddr_funnel0_out0: endpoint {
						remote-endpoint =
						<&ddr_tpda_in0>;
					};
				};
			};

			in-ports {
				#address-cells = <1>;
				#size-cells = <0>;

				port@0 {
					reg = <0>;
					ddr_funnel0_in0: endpoint {
						remote-endpoint =
						<&ddr_tpdm0_out>;
					};
				};
			};
		};

		tpdm@4e20000 {
			compatible = "qcom,coresight-tpdm", "arm,primecell";
			reg = <0x0 0x4e20000 0x0 0x1000>;
			device-name = "tpdm_ddr_ch1";

			clocks = <&aoss_qmp>;
			clock-names = "apb_pclk";

			qcom,dsb-element-bits = <32>;
			qcom,dsb-msrs-num = <32>;

			out-ports {
				port {
					ddr_tpdm1_out: endpoint {
						remote-endpoint =
						<&ddr_funnel1_in0>;
					};
				};
			};
		};

		cti@4e21000 {
			compatible = "arm,coresight-cti", "arm,primecell";
			reg = <0x0 0x4e21000 0x0 0x1000>;
			device-name = "cti_ddr_ch1";

			clocks = <&aoss_qmp>;
			clock-names = "apb_pclk";
			qcom,extended_cti;
		};

		funnel@4e22000 {
			compatible = "arm,coresight-dynamic-funnel", "arm,primecell";
			reg = <0x0 0x4e22000 0x0 0x1000>;

			clocks = <&aoss_qmp>;
			clock-names = "apb_pclk";

			out-ports {
				port {
					ddr_funnel1_out0: endpoint {
						remote-endpoint =
						<&ddr_tpda_in1>;
					};
				};
			};

			in-ports {
				#address-cells = <1>;
				#size-cells = <0>;

				port@0 {
					reg = <0>;
					ddr_funnel1_in0: endpoint {
						remote-endpoint =
						<&ddr_tpdm1_out>;
					};
				};
			};
		};

		cti@4e34000 {
			compatible = "arm,coresight-cti", "arm,primecell";
			reg = <0x0 0x4e34000 0x0 0x1000>;
			device-name = "cti_ddr_2";

			clocks = <&aoss_qmp>;
			clock-names = "apb_pclk";
			qcom,extended_cti;
		};

		etm@6040000 {
			compatible = "arm,primecell";
			reg = <0x0 0x6040000 0x0 0x1000>;
			cpu = <&CPU0>;

			clocks = <&aoss_qmp>;
			clock-names = "apb_pclk";
			arm,coresight-loses-context-with-cpu;
			qcom,skip-power-up;

			out-ports {
				port {
					etm0_out: endpoint {
						remote-endpoint =
						<&apss_funnel0_in0>;
					};
				};
			};
		};

		etm@6140000 {
			compatible = "arm,primecell";
			reg = <0x0 0x6140000 0x0 0x1000>;
			cpu = <&CPU1>;

			clocks = <&aoss_qmp>;
			clock-names = "apb_pclk";
			arm,coresight-loses-context-with-cpu;
			qcom,skip-power-up;

			out-ports {
				port {
					etm1_out: endpoint {
						remote-endpoint =
						<&apss_funnel0_in1>;
					};
				};
			};
		};

		etm@6240000 {
			compatible = "arm,primecell";
			reg = <0x0 0x6240000 0x0 0x1000>;
			cpu = <&CPU2>;

			clocks = <&aoss_qmp>;
			clock-names = "apb_pclk";
			arm,coresight-loses-context-with-cpu;
			qcom,skip-power-up;

			out-ports {
				port {
					etm2_out: endpoint {
						remote-endpoint =
						<&apss_funnel0_in2>;
					};
				};
			};
		};

		etm@6340000 {
			compatible = "arm,primecell";
			reg = <0x0 0x6340000 0x0 0x1000>;
			cpu = <&CPU3>;

			clocks = <&aoss_qmp>;
			clock-names = "apb_pclk";
			arm,coresight-loses-context-with-cpu;
			qcom,skip-power-up;

			out-ports {
				port {
					etm3_out: endpoint {
						remote-endpoint =
						<&apss_funnel0_in3>;
					};
				};
			};
		};

		etm@6440000 {
			compatible = "arm,primecell";
			reg = <0x0 0x6440000 0x0 0x1000>;
			cpu = <&CPU4>;

			clocks = <&aoss_qmp>;
			clock-names = "apb_pclk";
			arm,coresight-loses-context-with-cpu;
			qcom,skip-power-up;

			out-ports {
				port {
					etm4_out: endpoint {
						remote-endpoint =
						<&apss_funnel0_in4>;
					};
				};
			};
		};

		etm@6540000 {
			compatible = "arm,primecell";
			reg = <0x0 0x6540000 0x0 0x1000>;
			cpu = <&CPU5>;

			clocks = <&aoss_qmp>;
			clock-names = "apb_pclk";
			arm,coresight-loses-context-with-cpu;
			qcom,skip-power-up;

			out-ports {
				port {
					etm5_out: endpoint {
						remote-endpoint =
						<&apss_funnel0_in5>;
					};
				};
			};
		};

		etm@6640000 {
			compatible = "arm,primecell";
			reg = <0x0 0x6640000 0x0 0x1000>;
			cpu = <&CPU6>;

			clocks = <&aoss_qmp>;
			clock-names = "apb_pclk";
			arm,coresight-loses-context-with-cpu;
			qcom,skip-power-up;

			out-ports {
				port {
					etm6_out: endpoint {
						remote-endpoint =
						<&apss_funnel0_in6>;
					};
				};
			};
		};

		etm@6740000 {
			compatible = "arm,primecell";
			reg = <0x0 0x6740000 0x0 0x1000>;
			cpu = <&CPU7>;

			clocks = <&aoss_qmp>;
			clock-names = "apb_pclk";
			arm,coresight-loses-context-with-cpu;
			qcom,skip-power-up;

			out-ports {
				port {
					etm7_out: endpoint {
						remote-endpoint =
						<&apss_funnel0_in7>;
					};
				};
			};
		};

		funnel@6800000 {
			compatible = "arm,coresight-dynamic-funnel", "arm,primecell";
			reg = <0x0 0x6800000 0x0 0x1000>;

			clocks = <&aoss_qmp>;
			clock-names = "apb_pclk";

			out-ports {
				port {
					apss_funnel0_out: endpoint {
						remote-endpoint =
						<&apss_funnel1_in0>;
					};
				};
			};

			in-ports {
				#address-cells = <1>;
				#size-cells = <0>;

				port@0 {
					reg = <0>;
					apss_funnel0_in0: endpoint {
						remote-endpoint =
						<&etm0_out>;
					};
				};

				port@1 {
					reg = <1>;
					apss_funnel0_in1: endpoint {
						remote-endpoint =
						<&etm1_out>;
					};
				};

				port@2 {
					reg = <2>;
					apss_funnel0_in2: endpoint {
						remote-endpoint =
						<&etm2_out>;
					};
				};

				port@3 {
					reg = <3>;
					apss_funnel0_in3: endpoint {
						remote-endpoint =
						<&etm3_out>;
					};
				};

				port@4 {
					reg = <4>;
					apss_funnel0_in4: endpoint {
						remote-endpoint =
						<&etm4_out>;
					};
				};

				port@5 {
					reg = <5>;
					apss_funnel0_in5: endpoint {
						remote-endpoint =
						<&etm5_out>;
					};
				};

				port@6 {
					reg = <6>;
					apss_funnel0_in6: endpoint {
						remote-endpoint =
						<&etm6_out>;
					};
				};

				port@7 {
					reg = <7>;
					apss_funnel0_in7: endpoint {
						remote-endpoint =
						<&etm7_out>;
					};
				};
			};
		};

		funnel@6810000 {
			compatible = "arm,coresight-dynamic-funnel", "arm,primecell";
			reg = <0x0 0x6810000 0x0 0x1000>;

			clocks = <&aoss_qmp>;
			clock-names = "apb_pclk";

			out-ports {
				port {
					apss_funnel1_out: endpoint {
						remote-endpoint =
						<&funnel1_in4>;
					};
				};
			};

			in-ports {
				#address-cells = <1>;
				#size-cells = <0>;

				port@0 {
					reg = <0>;
					apss_funnel1_in0: endpoint {
						remote-endpoint =
						<&apss_funnel0_out>;
					};
				};

				port@3 {
					reg = <3>;
					apss_funnel1_in3: endpoint {
						remote-endpoint =
						<&apss_tpda_out>;
					};
				};
			};
		};

		cti@682b000 {
			compatible = "arm,coresight-cti", "arm,primecell";
			reg = <0x0 0x682b000 0x0 0x1000>;
			device-name = "cti_apss";

			clocks = <&aoss_qmp>;
			clock-names = "apb_pclk";
		};

		tpdm@6860000 {
			compatible = "qcom,coresight-tpdm", "arm,primecell";
			reg = <0x0 0x6860000 0x0 0x1000>;
			device-name = "tpdm_actpm";

			clocks = <&aoss_qmp>;
			clock-names = "apb_pclk";

			qcom,cmb-element-bits = <64>;
			qcom,cmb-msrs-num = <32>;

			out-ports {
				port {
					apss_tpdm3_out: endpoint {
						remote-endpoint =
						<&apss_tpda_in3>;
					};
				};
			};
		};

		tpdm@6861000 {
			compatible = "qcom,coresight-tpdm", "arm,primecell";
			reg = <0x0 0x6861000 0x0 0x1000>;
			device-name = "tpdm_apss";

			clocks = <&aoss_qmp>;
			clock-names = "apb_pclk";

			qcom,dsb-element-bits = <32>;
			qcom,dsb-msrs-num = <32>;

			out-ports {
				port {
					apss_tpdm4_out: endpoint {
						remote-endpoint =
						<&apss_tpda_in4>;
					};
				};
			};
		};

		cti@6862000 {
			compatible = "arm,coresight-cti", "arm,primecell";
			reg = <0x0 0x6862000 0x0 0x1000>;
			device-name = "cti_apss_riscv";

			clocks = <&aoss_qmp>;
			clock-names = "apb_pclk";
			qcom,extended_cti;
		};

		tpda@6863000 {
			compatible = "qcom,coresight-tpda", "arm,primecell";
			reg = <0x0 0x6863000 0x0 0x1000>;
			device-name = "tpda_apss";

			clocks = <&aoss_qmp>;
			clock-names = "apb_pclk";

			out-ports {
				port {
					apss_tpda_out: endpoint {
						remote-endpoint =
						<&apss_funnel1_in3>;
					};
				};
			};

			in-ports {
				#address-cells = <1>;
				#size-cells = <0>;

				port@0 {
					reg = <0>;
					apss_tpda_in0: endpoint {
						remote-endpoint =
						<&apss_tpdm0_out>;
					};
				};

				port@1 {
					reg = <1>;
					apss_tpda_in1: endpoint {
						remote-endpoint =
						<&apss_tpdm1_out>;
					};
				};

				port@2 {
					reg = <2>;
					apss_tpda_in2: endpoint {
						remote-endpoint =
						<&apss_tpdm2_out>;
					};
				};

				port@3 {
					reg = <3>;
					apss_tpda_in3: endpoint {
						remote-endpoint =
						<&apss_tpdm3_out>;
					};
				};

				port@4 {
					reg = <4>;
					apss_tpda_in4: endpoint {
						remote-endpoint =
						<&apss_tpdm4_out>;
					};
				};
			};
		};

		tpdm@68a0000 {
			compatible = "qcom,coresight-tpdm", "arm,primecell";
			reg = <0x0 0x68a0000 0x0 0x1000>;
			device-name = "tpdm_llm_gold";

			clocks = <&aoss_qmp>;
			clock-names = "apb_pclk";

			qcom,cmb-element-bits = <32>;
			qcom,cmb-msrs-num = <32>;

			out-ports {
				port {
					apss_tpdm1_out: endpoint {
						remote-endpoint =
						<&apss_tpda_in1>;
					};
				};
			};
		};

		tpdm@68b0000 {
			compatible = "qcom,coresight-tpdm", "arm,primecell";
			reg = <0x0 0x68b0000 0x0 0x1000>;
			device-name = "tpdm_llm_silver";

			clocks = <&aoss_qmp>;
			clock-names = "apb_pclk";

			qcom,cmb-element-bits = <32>;
			qcom,cmb-msrs-num = <32>;

			out-ports {
				port {
					apss_tpdm0_out: endpoint {
						remote-endpoint =
						<&apss_tpda_in0>;
					};
				};
			};
		};

		tpdm@68c0000 {
			compatible = "qcom,coresight-tpdm", "arm,primecell";
			reg = <0x0 0x68c0000 0x0 0x1000>;
			device-name = "tpdm_ext_dsb";

			clocks = <&aoss_qmp>;
			clock-names = "apb_pclk";

			qcom,dsb-element-bits = <32>;
			qcom,dsb-msrs-num = <32>;

			out-ports {
				port {
					apss_tpdm2_out: endpoint {
						remote-endpoint =
						<&apss_tpda_in2>;
					};
				};
			};
		};

		cti@68e0000 {
			compatible = "arm,coresight-cti", "arm,primecell";
			reg = <0x0 0x68e0000 0x0 0x1000>;
			device-name = "cti_llm_gold";

			clocks = <&aoss_qmp>;
			clock-names = "apb_pclk";
		};

		cti@68f0000 {
			compatible = "arm,coresight-cti", "arm,primecell";
			reg = <0x0 0x68f0000 0x0 0x1000>;
			device-name = "cti_llm_silver";

			clocks = <&aoss_qmp>;
			clock-names = "apb_pclk";
		};

		cti@6900000 {
			compatible = "arm,coresight-cti", "arm,primecell";
			reg = <0x0 0x6900000 0x0 0x1000>;
			device-name = "cti_ext_dsb";

			clocks = <&aoss_qmp>;
			clock-names = "apb_pclk";
		};
	};

	lpi_funnel {
		compatible = "arm,coresight-static-funnel";

		clocks = <&aoss_qmp>;
		clock-names = "apb_pclk";

		out-ports {
			port {
				lpi_funnel_out: endpoint {
					remote-endpoint =
						<&aoss_funnel_in5>;
				};
			};
		};

		in-ports {
			#address-cells = <1>;
			#size-cells = <0>;

			port@0 {
				reg = <0>;
				lpi_funnel_in0: endpoint {
					remote-endpoint =
					<&audio_out>;
				};
			};

			port@5 {
				reg = <5>;
				lpi_funnel_in5: endpoint {
					remote-endpoint =
					<&lpi_tpda_out>;
				};
			};
		};
	};

	arch_timer: timer {
		compatible = "arm,armv8-timer";
		interrupts = <GIC_PPI 13 (GIC_CPU_MASK_SIMPLE(8) | IRQ_TYPE_LEVEL_LOW)>,
			     <GIC_PPI 14 (GIC_CPU_MASK_SIMPLE(8) | IRQ_TYPE_LEVEL_LOW)>,
			     <GIC_PPI 11 (GIC_CPU_MASK_SIMPLE(8) | IRQ_TYPE_LEVEL_LOW)>,
			     <GIC_PPI 12 (GIC_CPU_MASK_SIMPLE(8) | IRQ_TYPE_LEVEL_LOW)>;
	};

	turing0-etm0 {
		compatible = "qcom,coresight-remote-etm";
		device-name = "turing_etm0";

		qcom,inst-id = <13>;
		atid = <38 39>;

		out-ports {
			port {
				turing0_etm0_out: endpoint {
					remote-endpoint =
					<&turing0_funnel_in3>;
				};
			};
		};
	};
};
